VERSION "HIPBNNNYNNNNNNNNNNNNNNNNNNNNNNNNNNNNNNNNNN/4/%%/4/'%**4NNN///"

NS_ :

BS_:

BU_: EXXOTEST__XXX

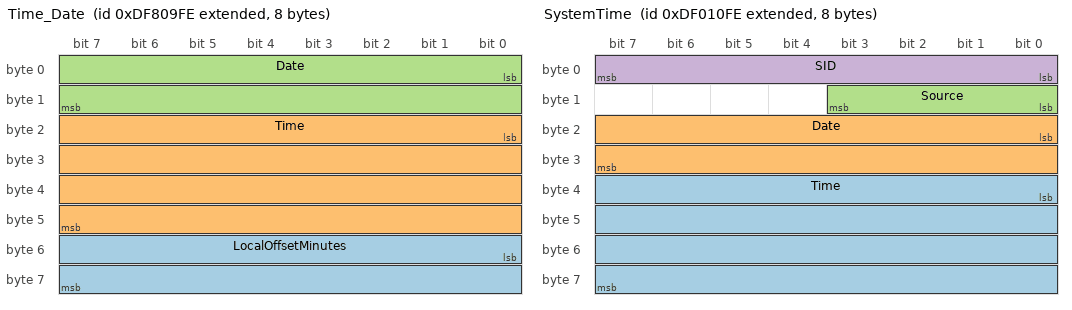
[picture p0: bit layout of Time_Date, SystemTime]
BO_ 2381842942 Time_Date: 8 EXXOTEST__XXX
 SG_ LocalOffsetMinutes : 48|16@1- (1,0) [-32764|32764] "mins"  EXXOTEST__XXX
 SG_ Time : 16|32@1+ (0.0001,0) [0|86401] "sec"  EXXOTEST__XXX
 SG_ Date : 0|16@1+ (1,0) [0|65532] "day"  EXXOTEST__XXX

BO_ 2381911550 TimeTo_FromMark: 10 EXXOTEST__XXX
 SG_ MarkID : 48|32@1+ (1,0) [0|4294967292] ""  EXXOTEST__XXX
 SG_ MarkType : 40|4@1+ (1,0) [0|15] ""  EXXOTEST__XXX
 SG_ TimeElapsedTogoToMark : 8|32@1- (0.001,0) [-2148000|2148000] "sec"  EXXOTEST__XXX
 SG_ SID : 0|8@1+ (1,0) [0|252] ""  EXXOTEST__XXX

BO_ 2583499006 TideStationData: 23 EXXOTEST__XXX
 SG_ StationNameString : 168|16@1+ (1,0) [0|255] "ASCII"  EXXOTEST__XXX
 SG_ StationIDString : 152|16@1+ (1,0) [0|255] "ASCII"  EXXOTEST__XXX
 SG_ TideLevelStandardDeviation : 136|16@1+ (0.01,0) [0|655.32] "m"  EXXOTEST__XXX
 SG_ TideLevel : 120|16@1- (0.001,0) [-32.764|32.764] "m"  EXXOTEST__XXX
 SG_ StationLocationLongitude : 88|32@1- (1,0) [-180|180] "deg"  EXXOTEST__XXX
 SG_ StationLocationLatitude : 56|32@1- (1,0) [-90|90] "deg"  EXXOTEST__XXX
 SG_ MeasurementTime : 24|32@1+ (0.0001,0) [0|86401] "sec"  EXXOTEST__XXX
 SG_ MeasurementDate : 8|16@1+ (1,0) [0|65532] "day"  EXXOTEST__XXX
 SG_ TideTendency : 4|2@1+ (1,0) [0|3] ""  EXXOTEST__XXX
 SG_ Mode : 0|4@1+ (1,0) [0|15] ""  EXXOTEST__XXX

BO_ 2381320446 SystemTime: 8 EXXOTEST__XXX
 SG_ Time : 32|32@1+ (0.0001,0) [0|86401] "sec"  EXXOTEST__XXX
 SG_ Date : 16|16@1+ (1,0) [0|65532] "day"  EXXOTEST__XXX
 SG_ Source : 8|4@1+ (1,0) [0|15] ""  EXXOTEST__XXX
 SG_ SID : 0|8@1+ (1,0) [0|252] ""  EXXOTEST__XXX

BO_ 2381451006 SwitchBankCtrl: 8 EXXOTEST__XXX
 SG_ Switch28 : 62|2@1+ (1,0) [0|3] ""  EXXOTEST__XXX
 SG_ Switch27 : 60|2@1+ (1,0) [0|3] ""  EXXOTEST__XXX
 SG_ Switch26 : 58|2@1+ (1,0) [0|3] ""  EXXOTEST__XXX
 SG_ Switch25 : 56|2@1+ (1,0) [0|3] ""  EXXOTEST__XXX
 SG_ Switch24 : 54|2@1+ (1,0) [0|3] ""  EXXOTEST__XXX
 SG_ Switch23 : 52|2@1+ (1,0) [0|3] ""  EXXOTEST__XXX
 SG_ Switch22 : 50|2@1+ (1,0) [0|3] ""  EXXOTEST__XXX
 SG_ Switch21 : 48|2@1+ (1,0) [0|3] ""  EXXOTEST__XXX
 SG_ Switch20 : 46|2@1+ (1,0) [0|3] ""  EXXOTEST__XXX
 SG_ Switch19 : 44|2@1+ (1,0) [0|3] ""  EXXOTEST__XXX
 SG_ Switch18 : 42|2@1+ (1,0) [0|3] ""  EXXOTEST__XXX
 SG_ Switch17 : 40|2@1+ (1,0) [0|3] ""  EXXOTEST__XXX
 SG_ Switch16 : 38|2@1+ (1,0) [0|3] ""  EXXOTEST__XXX
 SG_ Switch15 : 36|2@1+ (1,0) [0|3] ""  EXXOTEST__XXX
 SG_ Switch14 : 34|2@1+ (1,0) [0|3] ""  EXXOTEST__XXX
 SG_ Switch13 : 32|2@1+ (1,0) [0|3] ""  EXXOTEST__XXX
 SG_ Switch12 : 30|2@1+ (1,0) [0|3] ""  EXXOTEST__XXX
 SG_ Switch11 : 28|2@1+ (1,0) [0|3] ""  EXXOTEST__XXX
 SG_ Switch10 : 26|2@1+ (1,0) [0|3] ""  EXXOTEST__XXX
 SG_ Switch9 : 24|2@1+ (1,0) [0|3] ""  EXXOTEST__XXX
 SG_ Switch8 : 22|2@1+ (1,0) [0|3] ""  EXXOTEST__XXX
 SG_ Switch7 : 20|2@1+ (1,0) [0|3] ""  EXXOTEST__XXX
 SG_ Switch6 : 18|2@1+ (1,0) [0|3] ""  EXXOTEST__XXX
 SG_ Switch5 : 16|2@1+ (1,0) [0|3] ""  EXXOTEST__XXX
 SG_ Switch4 : 14|2@1+ (1,0) [0|3] ""  EXXOTEST__XXX
 SG_ Switch3 : 12|2@1+ (1,0) [0|3] ""  EXXOTEST__XXX
 SG_ Switch2 : 10|2@1+ (1,0) [0|3] ""  EXXOTEST__XXX
 SG_ Switch1 : 8|2@1+ (1,0) [0|3] ""  EXXOTEST__XXX
 SG_ SwitchBankInstance : 0|8@1+ (1,0) [0|252] ""  EXXOTEST__XXX

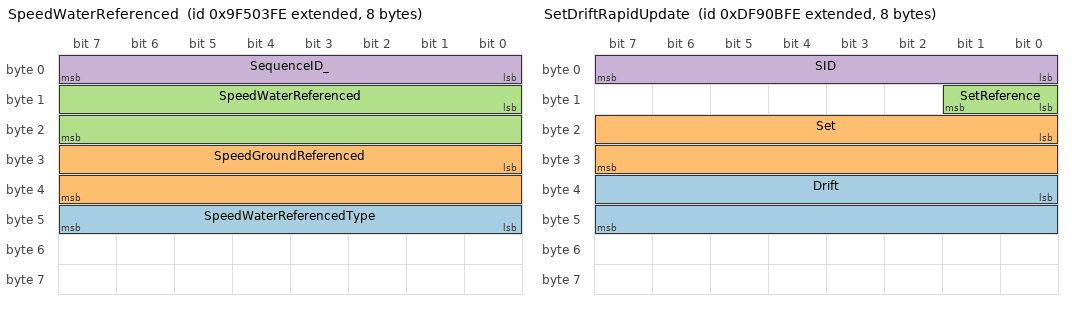
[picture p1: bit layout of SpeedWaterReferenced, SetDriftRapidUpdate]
BO_ 2314535934 SpeedWaterReferenced: 8 EXXOTEST__XXX
 SG_ SpeedWaterReferencedType : 40|8@1+ (1,0) [0|0] ""  EXXOTEST__XXX
 SG_ SpeedGroundReferenced : 24|16@1+ (0.01,0) [0|655.32] "m/s"  EXXOTEST__XXX
 SG_ SpeedWaterReferenced : 8|16@1+ (0.01,0) [0|655.32] "m/s"  EXXOTEST__XXX
 SG_ SequenceID_ : 0|8@1+ (1,0) [0|252] ""  EXXOTEST__XXX

BO_ 2315129086 SmallCraftStatus: 8 EXXOTEST__XXX
 SG_ StarboardTrimTab : 8|8@1- (1,0) [-124|124] ""  EXXOTEST__XXX
 SG_ PortTrimTab : 0|8@1- (1,0) [-124|124] ""  EXXOTEST__XXX

BO_ 2381908990 SetDriftRapidUpdate: 8 EXXOTEST__XXX
 SG_ Drift : 32|16@1+ (0.01,0) [0|655.32] "m/s"  EXXOTEST__XXX
 SG_ Set : 16|16@1+ (0.0001,0) [0|6.28318] "rad"  EXXOTEST__XXX
 SG_ SetReference : 8|2@1+ (1,0) [0|3] ""  EXXOTEST__XXX
 SG_ SID : 0|8@1+ (1,0) [0|252] ""  EXXOTEST__XXX

BO_ 2583499262 SalinityStationData: 25 EXXOTEST__XXX

BO_ 2650543102 RouteAndWPServiceRouteWPNamePos: 14 EXXOTEST__XXX
 SG_ WPName : 96|16@1+ (1,0) [0|255] "ASCII"  EXXOTEST__XXX
 SG_ WPID : 80|16@1+ (1,0) [0|65532] ""  EXXOTEST__XXX
 SG_ RouteID : 64|16@1+ (1,0) [0|65532] ""  EXXOTEST__XXX
 SG_ DatabaseID : 48|16@1+ (1,0) [0|65532] ""  EXXOTEST__XXX
 SG_ NumberOfWPsInRoute : 32|16@1+ (1,0) [0|65532] ""  EXXOTEST__XXX
 SG_ nItems : 16|16@1+ (1,0) [0|65532] ""  EXXOTEST__XXX
 SG_ StartRPS : 0|16@1+ (1,0) [0|65532] ""  EXXOTEST__XXX

BO_ 2650543358 RouteAndWPServiceRouteWPName: 14 EXXOTEST__XXX
 SG_ WPName : 96|16@1+ (1,0) [0|255] "ASCII"  EXXOTEST__XXX
 SG_ WPID : 80|16@1+ (1,0) [0|65532] ""  EXXOTEST__XXX
 SG_ RouteID : 64|16@1+ (1,0) [0|65532] ""  EXXOTEST__XXX
 SG_ DatabaseID : 48|16@1+ (1,0) [0|65532] ""  EXXOTEST__XXX
 SG_ NumberOfWPsInRoute : 32|16@1+ (1,0) [0|65532] ""  EXXOTEST__XXX
 SG_ nItems : 16|16@1+ (1,0) [0|65532] ""  EXXOTEST__XXX
 SG_ StartRPS : 0|16@1+ (1,0) [0|65532] ""  EXXOTEST__XXX

BO_ 2650542590 RouteAndWPServiceRouteList: 12 EXXOTEST__XXX
 SG_ RouteName : 80|16@1+ (1,0) [0|255] "ASCII"  EXXOTEST__XXX
 SG_ RouteID : 64|16@1+ (1,0) [0|65532] ""  EXXOTEST__XXX
 SG_ DatabaseID : 48|16@1+ (1,0) [0|65532] ""  EXXOTEST__XXX
 SG_ NmbrOfRoutesAvailableInDatabase : 32|16@1+ (1,0) [0|65532] ""  EXXOTEST__XXX
 SG_ nItems : 16|16@1+ (1,0) [0|65532] ""  EXXOTEST__XXX
 SG_ StartRouteID : 0|16@1+ (1,0) [0|65532] ""  EXXOTEST__XXX

BO_ 2650544126 RouteAndWPServiceRouteComment: 13 EXXOTEST__XXX
 SG_ Comment : 80|24@1+ (1,0) [0|255] ""  EXXOTEST__XXX
 SG_ RouteID : 64|16@1+ (1,0) [0|65532] ""  EXXOTEST__XXX
 SG_ DatabaseID : 48|16@1+ (1,0) [0|65532] ""  EXXOTEST__XXX
 SG_ NumberOfRoutesWithComments : 32|16@1+ (1,0) [0|65532] ""  EXXOTEST__XXX
 SG_ nItems : 16|16@1+ (1,0) [0|65532] ""  EXXOTEST__XXX
 SG_ StartRouteID : 0|16@1+ (1,0) [0|65532] ""  EXXOTEST__XXX

BO_ 2650544638 RouteAndWPServiceRadiusOfTurn: 14 EXXOTEST__XXX
 SG_ RadiusOfTurn : 96|16@1- (1,0) [-32764|32764] "m"  EXXOTEST__XXX
 SG_ RPS : 80|16@1+ (1,0) [0|65532] ""  EXXOTEST__XXX
 SG_ RouteID : 64|16@1+ (1,0) [0|65532] ""  EXXOTEST__XXX
 SG_ DatabaseID : 48|16@1+ (1,0) [0|65532] ""  EXXOTEST__XXX
 SG_ NmbrOfWypntsWthASpcfcRdusOfTurn : 32|16@1+ (1,0) [0|65532] ""  EXXOTEST__XXX
 SG_ nItems : 16|16@1+ (1,0) [0|65532] ""  EXXOTEST__XXX
 SG_ StartRPS : 0|16@1+ (1,0) [0|65532] ""  EXXOTEST__XXX

BO_ 2650542334 RouteAndWPServiceDatabaseList: 10 EXXOTEST__XXX
 SG_ DatabaseName : 64|16@1+ (1,0) [0|255] "ASCII"  EXXOTEST__XXX
 SG_ DatabaseID : 48|16@1+ (1,0) [0|65532] ""  EXXOTEST__XXX
 SG_ NumberOfDatabasesAvailable : 32|16@1+ (1,0) [0|65532] ""  EXXOTEST__XXX
 SG_ nItems : 16|16@1+ (1,0) [0|65532] ""  EXXOTEST__XXX
 SG_ StartDatabaseID : 0|16@1+ (1,0) [0|65532] ""  EXXOTEST__XXX

BO_ 2314277886 RateOfTurn: 8 EXXOTEST__XXX
 SG_ RateOfTurn : 8|16@1- (1,0) [-32768|32767] "rad/s"  EXXOTEST__XXX
 SG_ SequenceID_ : 0|8@1+ (1,0) [0|252] ""  EXXOTEST__XXX

BO_ 2382039038 RadioFrequency_Mode_Power: 14 EXXOTEST__XXX
 SG_ RadioChannel : 64|48@1+ (1,0) [0|255] "ASCII"  EXXOTEST__XXX
 SG_ TxFrequency : 32|32@1+ (10,0) [0|327040] "Hz"  EXXOTEST__XXX
 SG_ RxFrequency : 0|32@1+ (10,0) [0|327040] "Hz"  EXXOTEST__XXX

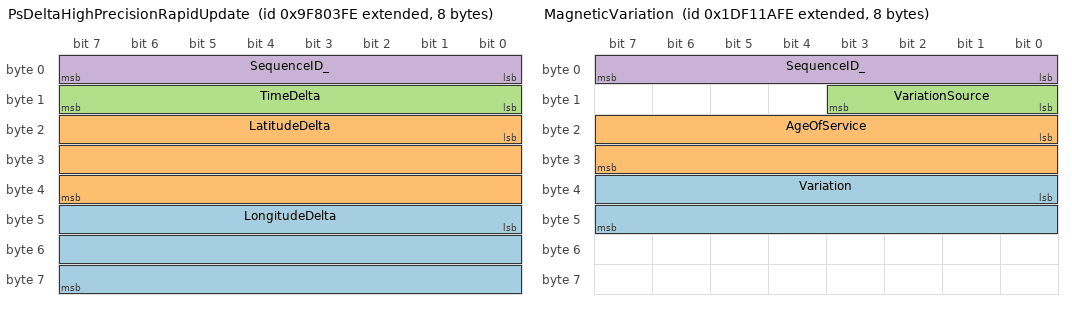
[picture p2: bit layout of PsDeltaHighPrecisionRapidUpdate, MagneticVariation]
BO_ 2314732542 PsDeltaHighPrecisionRapidUpdate: 8 EXXOTEST__XXX
 SG_ LongitudeDelta : 40|24@1- (1E-05,0) [-83|83] "s"  EXXOTEST__XXX
 SG_ LatitudeDelta : 16|24@1- (1E-05,0) [-83|83] "s"  EXXOTEST__XXX
 SG_ TimeDelta : 8|8@1+ (0.005,0) [0|1.26] "sec"  EXXOTEST__XXX
 SG_ SequenceID_ : 0|8@1+ (1,0) [0|252] ""  EXXOTEST__XXX

BO_ 2314732030 PosRapidUpdate: 8 EXXOTEST__XXX
 SG_ Longitude_ : 32|32@1- (1,0) [-180|180] "deg"  EXXOTEST__XXX
 SG_ Latitude_ : 0|32@1- (1,0) [-90|90] "deg"  EXXOTEST__XXX

BO_ 2583234046 NavigationRoute_WPInformation: 16 EXXOTEST__XXX
 SG_ WPName : 112|16@1+ (1,0) [0|255] "ASCII"  EXXOTEST__XXX
 SG_ RouteName : 72|16@1+ (1,0) [0|255] "ASCII"  EXXOTEST__XXX
 SG_ SpplmntaryRoute_WPDataAvailable : 68|2@1+ (1,0) [0|3] ""  EXXOTEST__XXX
 SG_ NavigationDirectionInRoute : 64|4@1+ (1,0) [0|15] ""  EXXOTEST__XXX
 SG_ RouteID : 48|16@1+ (1,0) [0|65532] ""  EXXOTEST__XXX
 SG_ DatabaseID : 32|16@1+ (1,0) [0|65532] ""  EXXOTEST__XXX
 SG_ nItems : 16|16@1+ (1,0) [0|65532] ""  EXXOTEST__XXX
 SG_ StartRPS : 0|16@1+ (1,0) [0|65532] ""  EXXOTEST__XXX

BO_ 2381907198 NavigationData: 34 EXXOTEST__XXX
 SG_ WaypointClosingVelocity : 256|16@1- (0.01,0) [-327.66|327.66] "m/s"  EXXOTEST__XXX
 SG_ DestinationWptLongitude : 224|32@1- (1,0) [-180|180] "deg"  EXXOTEST__XXX
 SG_ DestinationWptLatitude : 192|32@1- (1,0) [-90|90] "deg"  EXXOTEST__XXX
 SG_ DestinationWaypointNumber : 160|32@1+ (1,0) [0|4294967292] ""  EXXOTEST__XXX
 SG_ OriginWaypointNumber : 128|32@1+ (1,0) [0|4294967292] ""  EXXOTEST__XXX
 SG_ BearingPosToDestinationWaypoint : 112|16@1+ (0.0001,0) [0|6.28318] "rad"  EXXOTEST__XXX
 SG_ BaringiginToDestinationWaypoint : 96|16@1+ (0.0001,0) [0|6.28318] "rad"  EXXOTEST__XXX
 SG_ ETADate : 80|16@1+ (1,0) [0|65532] "day"  EXXOTEST__XXX
 SG_ ETATime : 48|32@1+ (0.0001,0) [0|86401] "sec"  EXXOTEST__XXX
 SG_ CalculationType : 46|2@1+ (1,0) [0|3] ""  EXXOTEST__XXX
 SG_ ArrivalCircleEntered : 44|2@1+ (1,0) [0|3] ""  EXXOTEST__XXX
 SG_ PerpendicularCrossed : 42|2@1+ (1,0) [0|3] ""  EXXOTEST__XXX
 SG_ Course_BearingRef : 40|2@1+ (1,0) [0|3] ""  EXXOTEST__XXX
 SG_ DistanceToDestinationWaypoint : 8|32@1+ (0.01,0) [0|42950000] "m"  EXXOTEST__XXX
 SG_ SID : 0|8@1+ (1,0) [0|252] ""  EXXOTEST__XXX

BO_ 2381184766 NMEARqGroupFunction: 15 EXXOTEST__XXX
 SG_ NumberOfRqedCmdedParameters m2 : 48|8@1+ (1,0) [0|252] ""  EXXOTEST__XXX
 SG_ VrblNmbrOfFldsFldNmber6Repeated3 m2 : 44|4@1+ (1,0) [0|15] ""  EXXOTEST__XXX
 SG_ FirstParameterErrorCode m2 : 40|4@1+ (1,0) [0|15] ""  EXXOTEST__XXX
 SG_ TransInterval_PriorityErrorCode m2 : 36|4@1+ (1,0) [0|15] ""  EXXOTEST__XXX
 SG_ RqedCmdedPGNBeingAcknowledged m2 : 12|24@1+ (1,0) [0|16777215] ""  EXXOTEST__XXX
 SG_ PGNErrorCode m2 : 8|4@1+ (1,0) [0|15] ""  EXXOTEST__XXX
 SG_ VrblNmbrOfFldsFldNmber6Repeated2 m1 : 56|8@1+ (1,0) [0|252] ""  EXXOTEST__XXX
 SG_ FeldNumberOfFirstCmdedParameter m1 : 48|8@1+ (1,0) [0|252] ""  EXXOTEST__XXX
 SG_ NmbrOfPrsOfCmddPrmetersToFollow m1 : 40|8@1+ (1,0) [0|252] ""  EXXOTEST__XXX
 SG_ PrioritySetting m1 : 32|4@1+ (1,0) [0|15] ""  EXXOTEST__XXX
 SG_ CmdedPGN m1 : 8|24@1+ (1,0) [0|16777215] ""  EXXOTEST__XXX
 SG_ VrblNmbrOfFldsFldNmber6Repeated m0 : 96|8@1+ (1,0) [0|252] ""  EXXOTEST__XXX
 SG_ FieldNumberOfFirstRqedParameter m0 : 88|8@1+ (1,0) [0|252] ""  EXXOTEST__XXX
 SG_ NmbrOfPrsOfRqParametersToFollow m0 : 80|8@1+ (1,0) [0|252] ""  EXXOTEST__XXX
 SG_ TransIntervalOffset m0 : 64|16@1+ (0.01,0) [0|655.32] "sec"  EXXOTEST__XXX
 SG_ TransInterval m0 : 32|32@1+ (0.001,0) [0|4295000] "sec"  EXXOTEST__XXX
 SG_ RqedPGN m0 : 8|24@1+ (1,0) [0|16777215] ""  EXXOTEST__XXX
 SG_ GroupFunctionRq_Cmd_Acknowledge M : 0|8@1+ (1,0) [0|252] ""  EXXOTEST__XXX

BO_ 2583500030 MooredBuoyStationData: 36 EXXOTEST__XXX
 SG_ StationIDString : 272|16@1+ (1,0) [0|255] "ASCII"  EXXOTEST__XXX
 SG_ WaterTemp : 256|16@1+ (0.01,0) [0|655.32] "°K"  EXXOTEST__XXX
 SG_ AirTemp : 240|16@1+ (0.01,0) [0|655.32] "°K"  EXXOTEST__XXX
 SG_ PressTendencyRate : 224|16@1- (10,0) [-327640|327640] "Pa/hr"  EXXOTEST__XXX
 SG_ AtmosphericPress : 208|16@1+ (100,0) [0|6553200] "Pa"  EXXOTEST__XXX
 SG_ DominateWavePeriod : 192|16@1+ (0.01,0) [0|655.32] "sec"  EXXOTEST__XXX
 SG_ WaveHeight : 176|16@1+ (0.01,0) [0|655.32] "m"  EXXOTEST__XXX
 SG_ WindGusts : 160|16@1+ (0.01,0) [0|655.32] "m/s"  EXXOTEST__XXX
 SG_ WindReference : 152|3@1+ (1,0) [0|7] ""  EXXOTEST__XXX
 SG_ WindDirection : 136|16@1+ (0.0001,0) [0|6.28318] "rad"  EXXOTEST__XXX
 SG_ WindSpeed : 120|16@1+ (0.01,0) [0|655.32] "m/s"  EXXOTEST__XXX
 SG_ StationLocationLongitude : 88|32@1- (1,0) [-180|180] "deg"  EXXOTEST__XXX
 SG_ StationLocationLatitude : 56|32@1- (1,0) [-90|90] "deg"  EXXOTEST__XXX
 SG_ MeasurementTime : 24|32@1+ (0.0001,0) [0|86401] "sec"  EXXOTEST__XXX
 SG_ MeasurementDate : 8|16@1+ (1,0) [0|65532] "day"  EXXOTEST__XXX
 SG_ Mode : 0|4@1+ (1,0) [0|15] ""  EXXOTEST__XXX

BO_ 2583499774 MeteorologicalStationData: 30 EXXOTEST__XXX
 SG_ StationNameString : 224|16@1+ (1,0) [0|255] "ASCII"  EXXOTEST__XXX
 SG_ StationIDString : 208|16@1+ (1,0) [0|255] "ASCII"  EXXOTEST__XXX
 SG_ AirTemp : 192|16@1+ (0.01,0) [0|655.32] "°K"  EXXOTEST__XXX
 SG_ AtmosphericPress : 176|16@1+ (100,0) [0|6553200] "Pa"  EXXOTEST__XXX
 SG_ WindGusts : 160|16@1+ (0.01,0) [0|655.32] "m/s"  EXXOTEST__XXX
 SG_ WindReference : 152|3@1+ (1,0) [0|7] ""  EXXOTEST__XXX
 SG_ WindDirection : 136|16@1+ (0.0001,0) [0|6.28318] "rad"  EXXOTEST__XXX
 SG_ WindSpeed : 120|16@1+ (0.01,0) [0|655.32] "m/s"  EXXOTEST__XXX
 SG_ StationLocationLongitude : 88|32@1- (1,0) [-180|180] "deg"  EXXOTEST__XXX
 SG_ StationLocationLatitude : 56|32@1- (1,0) [-90|90] "deg"  EXXOTEST__XXX
 SG_ MeasurementTime : 24|32@1+ (0.0001,0) [0|86401] "sec"  EXXOTEST__XXX
 SG_ MeasurementDate : 8|16@1+ (1,0) [0|65532] "day"  EXXOTEST__XXX
 SG_ Mode : 0|4@1+ (1,0) [0|15] ""  EXXOTEST__XXX

BO_ 2649823998 MagneticVariation: 8 EXXOTEST__XXX
 SG_ Variation : 32|16@1- (0.0001,0) [-3.14159|3.14159] "rad"  EXXOTEST__XXX
 SG_ AgeOfService : 16|16@1+ (1,0) [0|65532] "day"  EXXOTEST__XXX
 SG_ VariationSource : 8|4@1+ (1,0) [0|15] ""  EXXOTEST__XXX
 SG_ SequenceID_ : 0|8@1+ (1,0) [0|252] ""  EXXOTEST__XXX

BO_ 2382103806 LoranCTDData: 32 EXXOTEST__XXX
 SG_ Mode : 248|4@1+ (1,0) [0|15] ""  EXXOTEST__XXX
 SG_ StationStatusZ : 244|4@1+ (1,0) [0|15] ""  EXXOTEST__XXX
 SG_ StationStatusY : 240|4@1+ (1,0) [0|15] ""  EXXOTEST__XXX
 SG_ StationStatusX : 236|4@1+ (1,0) [0|15] ""  EXXOTEST__XXX
 SG_ StationStatusW : 232|4@1+ (1,0) [0|15] ""  EXXOTEST__XXX
 SG_ StationStatusV : 228|4@1+ (1,0) [0|15] ""  EXXOTEST__XXX
 SG_ StationStatusMaster : 224|4@1+ (1,0) [0|15] ""  EXXOTEST__XXX
 SG_ ZSecondTD : 192|32@1- (1,0) [-2.14|2.14] "sec"  EXXOTEST__XXX
 SG_ YSecondTD : 160|32@1- (1,0) [-2.14|2.14] "sec"  EXXOTEST__XXX
 SG_ XSecondTD : 128|32@1- (1,0) [-2.14|2.14] "sec"  EXXOTEST__XXX
 SG_ WSecondTD : 96|32@1- (1,0) [-2.14|2.14] "sec"  EXXOTEST__XXX
 SG_ VSecondTD : 64|32@1- (1,0) [-2.14|2.14] "sec"  EXXOTEST__XXX
 SG_ MasterRange : 32|32@1- (1,0) [-2.14|2.14] "sec"  EXXOTEST__XXX
 SG_ GroupRepetitionInterval : 0|32@1- (1,0) [-2.14|2.14] "sec"  EXXOTEST__XXX

BO_ 2382104318 LoranCSignalData: 8 EXXOTEST__XXX
 SG_ StationIdentifier : 32|8@1+ (1,0) [0|255] "ASCII"  EXXOTEST__XXX
 SG_ GroupRepetitionInterval : 0|32@1- (1,0) [-2.14|2.14] "sec"  EXXOTEST__XXX

BO_ 2382104062 LoranCRangeData: 32 EXXOTEST__XXX
 SG_ Mode : 248|4@1+ (1,0) [0|15] ""  EXXOTEST__XXX
 SG_ StationStatusZ : 244|4@1+ (1,0) [0|15] ""  EXXOTEST__XXX
 SG_ StationStatusY : 240|4@1+ (1,0) [0|15] ""  EXXOTEST__XXX
 SG_ StationStatusX : 236|4@1+ (1,0) [0|15] ""  EXXOTEST__XXX
 SG_ StationStatusW : 232|4@1+ (1,0) [0|15] ""  EXXOTEST__XXX
 SG_ StationStatusV : 228|4@1+ (1,0) [0|15] ""  EXXOTEST__XXX
 SG_ StationStatusMaster : 224|4@1+ (1,0) [0|15] ""  EXXOTEST__XXX
 SG_ ZSecondRange : 192|32@1- (1,0) [-2.14|2.14] "sec"  EXXOTEST__XXX
 SG_ YSecondRange : 160|32@1- (1,0) [-2.14|2.14] "sec"  EXXOTEST__XXX
 SG_ XSecondRange : 128|32@1- (1,0) [-2.14|2.14] "sec"  EXXOTEST__XXX
 SG_ WSecondRange : 96|32@1- (1,0) [-2.14|2.14] "sec"  EXXOTEST__XXX
 SG_ VSecondRange : 64|32@1- (1,0) [-2.14|2.14] "sec"  EXXOTEST__XXX
 SG_ MasterRange : 32|32@1- (1,0) [-2.14|2.14] "sec"  EXXOTEST__XXX
 SG_ GroupRepetitionInterval : 0|32@1- (1,0) [-2.14|2.14] "sec"  EXXOTEST__XXX

BO_ 2314274302 Heading_TrackCtrl: 21 EXXOTEST__XXX
 SG_ VesselHeading : 152|16@1+ (0.0001,0) [0|6.28318] "rad"  EXXOTEST__XXX
 SG_ OffTrackLimit : 136|16@1- (1,0) [-32764|32764] "m"  EXXOTEST__XXX
 SG_ RateOfTurnder : 120|16@1- (1,0) [-1|1] "rad/s"  EXXOTEST__XXX
 SG_ RadiusOfTurnder : 104|16@1- (1,0) [-32764|32764] "m"  EXXOTEST__XXX
 SG_ OffHeadingLimit : 88|16@1+ (0.0001,0) [0|6.28318] "rad"  EXXOTEST__XXX
 SG_ RudderLimit : 72|16@1+ (0.0001,0) [0|6.28318] "rad"  EXXOTEST__XXX
 SG_ Track : 56|16@1+ (0.0001,0) [0|6.28318] "rad"  EXXOTEST__XXX
 SG_ HeadingToSteer : 40|16@1+ (0.0001,0) [0|6.28318] "rad"  EXXOTEST__XXX
 SG_ CmdedRudderAngle : 24|16@1- (0.0001,0) [-3.14159|3.14159] "rad"  EXXOTEST__XXX
 SG_ CmdedRudderDirection : 21|3@1+ (1,0) [0|7] ""  EXXOTEST__XXX
 SG_ HeadingReference : 14|2@1+ (1,0) [0|3] ""  EXXOTEST__XXX
 SG_ TurnMode : 11|3@1+ (1,0) [0|7] ""  EXXOTEST__XXX
 SG_ SteerMode : 8|3@1+ (1,0) [0|7] ""  EXXOTEST__XXX
 SG_ Override : 6|2@1+ (1,0) [0|3] ""  EXXOTEST__XXX
 SG_ OffTrackLimitExceeded : 4|2@1+ (1,0) [0|3] ""  EXXOTEST__XXX
 SG_ OffHeadingLimitExceeded : 2|2@1+ (1,0) [0|3] ""  EXXOTEST__XXX
 SG_ RudderLimitExceeded : 0|2@1+ (1,0) [0|3] ""  EXXOTEST__XXX

BO_ 2583299582 GPSAlmanacData: 26 EXXOTEST__XXX
 SG_ ClockParameter2 : 195|11@1+ (1,0) [0|2047] ""  EXXOTEST__XXX
 SG_ ClockParameter1 : 184|11@1+ (1,0) [0|2047] ""  EXXOTEST__XXX
 SG_ MeanAnomaly : 160|24@1+ (1,0) [0|16777215] ""  EXXOTEST__XXX
 SG_ LongitudeOfAscensionNode : 136|24@1+ (1,0) [0|16777215] ""  EXXOTEST__XXX
 SG_ ArgumentOfPerigee : 112|24@1+ (1,0) [0|16777215] ""  EXXOTEST__XXX
 SG_ RootOfSemimajorAxis : 88|24@1+ (1,0) [0|16777215] ""  EXXOTEST__XXX
 SG_ RateOfRightAscension : 72|16@1+ (1,0) [0|65535] ""  EXXOTEST__XXX
 SG_ InclinationAngle : 56|16@1+ (1,0) [0|65535] ""  EXXOTEST__XXX
 SG_ AlmanacReferenceTime : 48|8@1+ (1,0) [0|255] ""  EXXOTEST__XXX
 SG_ Eccentricity : 32|16@1+ (1,0) [0|65535] ""  EXXOTEST__XXX
 SG_ SVHealthBits : 24|8@1+ (1,0) [0|255] ""  EXXOTEST__XXX
 SG_ GPSWeekNumber : 8|16@1+ (1,0) [0|65532] ""  EXXOTEST__XXX
 SG_ PRN : 0|8@1+ (1,0) [0|252] ""  EXXOTEST__XXX

BO_ 2583299326 GNSSSatsInView: 27 EXXOTEST__XXX
 SG_ PRNStatusN : 208|4@1+ (1,0) [0|15] ""  EXXOTEST__XXX
 SG_ RangeResidualsN : 176|32@1- (1E-05,0) [-21470|21470] "m"  EXXOTEST__XXX
 SG_ SNRN : 160|16@1- (0.01,0) [-327.64|327.64] "dB"  EXXOTEST__XXX
 SG_ AzimuthN : 144|16@1+ (0.0001,0) [0|6.28318] "rad"  EXXOTEST__XXX
 SG_ ElevationN : 128|16@1- (0.0001,0) [-3.14159|3.14159] "rad"  EXXOTEST__XXX
 SG_ PRNN : 120|8@1+ (1,0) [0|252] ""  EXXOTEST__XXX
 SG_ PRNStatus1 : 112|4@1+ (1,0) [0|15] ""  EXXOTEST__XXX
 SG_ RangeResiduals1 : 80|32@1- (1E-05,0) [-21470|21470] "m"  EXXOTEST__XXX
 SG_ SNR1 : 64|16@1- (0.01,0) [-327.64|327.64] "dB"  EXXOTEST__XXX
 SG_ Azimuth1 : 48|16@1+ (0.0001,0) [0|6.28318] "rad"  EXXOTEST__XXX
 SG_ Elevation1 : 32|16@1- (0.0001,0) [-3.14159|3.14159] "rad"  EXXOTEST__XXX
 SG_ PRN1 : 24|8@1+ (1,0) [0|252] ""  EXXOTEST__XXX
 SG_ NumberOfSVs_ : 16|8@1+ (1,0) [0|252] ""  EXXOTEST__XXX
 SG_ SID : 0|8@1+ (1,0) [0|252] ""  EXXOTEST__XXX
 SG_ RangeResidualMode : 8|2@1- (1,0) [0|3] ""  EXXOTEST__XXX

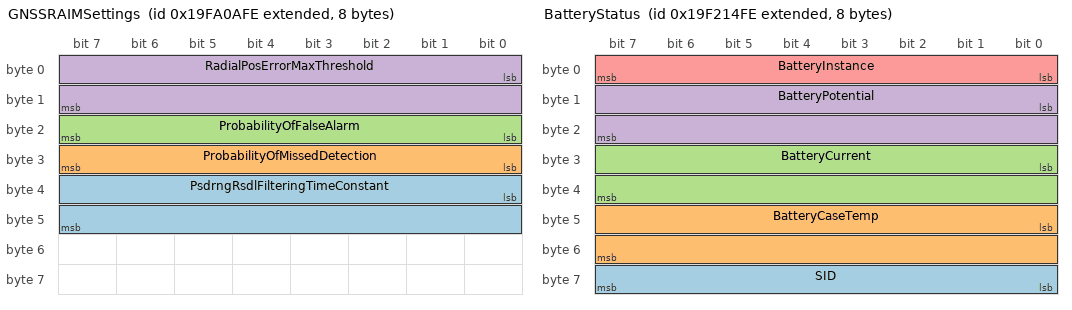
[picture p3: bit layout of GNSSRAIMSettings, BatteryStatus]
BO_ 2583300862 GNSSRAIMSettings: 8 EXXOTEST__XXX
 SG_ PsdrngRsdlFilteringTimeConstant : 32|16@1+ (1,0) [0|65532] "sec"  EXXOTEST__XXX
 SG_ ProbabilityOfMissedDetection : 24|8@1- (1,0) [-124|124] "%"  EXXOTEST__XXX
 SG_ ProbabilityOfFalseAlarm : 16|8@1- (1,0) [-124|124] ""  EXXOTEST__XXX
 SG_ RadialPosErrorMaxThreshold : 0|16@1+ (0.01,0) [0|655.32] "m"  EXXOTEST__XXX

BO_ 2583238398 BringAndDistanceBetweenTwoMarks: 17 EXXOTEST__XXX
 SG_ DestinationMarkID : 104|32@1+ (1,0) [0|4294967292] ""  EXXOTEST__XXX
 SG_ OriginMarkId : 72|32@1+ (1,0) [0|4294967292] ""  EXXOTEST__XXX
 SG_ DestinationMarkType : 68|4@1+ (1,0) [0|15] ""  EXXOTEST__XXX
 SG_ OriginMarkType : 64|4@1+ (1,0) [0|15] ""  EXXOTEST__XXX
 SG_ Distance : 32|32@1- (0.01,0) [-21470000|21470000] "m"  EXXOTEST__XXX
 SG_ BearingiginToDestination : 16|16@1+ (0.0001,0) [0|6.28318] "rad"  EXXOTEST__XXX
 SG_ CalculationType : 10|2@1+ (1,0) [0|3] ""  EXXOTEST__XXX
 SG_ BearingRef : 8|2@1+ (1,0) [0|3] ""  EXXOTEST__XXX
 SG_ SID : 0|8@1+ (1,0) [0|252] ""  EXXOTEST__XXX

BO_ 2381450750 BinarySwitchBankStatus: 8 EXXOTEST__XXX
 SG_ Indic28 : 62|2@1+ (1,0) [0|3] ""  EXXOTEST__XXX
 SG_ Indic27 : 60|2@1+ (1,0) [0|3] ""  EXXOTEST__XXX
 SG_ Indic26 : 58|2@1+ (1,0) [0|3] ""  EXXOTEST__XXX
 SG_ Indic25 : 56|2@1+ (1,0) [0|3] ""  EXXOTEST__XXX
 SG_ Indic24 : 54|2@1+ (1,0) [0|3] ""  EXXOTEST__XXX
 SG_ Indic23 : 52|2@1+ (1,0) [0|3] ""  EXXOTEST__XXX
 SG_ Indic22 : 50|2@1+ (1,0) [0|3] ""  EXXOTEST__XXX
 SG_ Indic21 : 48|2@1+ (1,0) [0|3] ""  EXXOTEST__XXX
 SG_ Indic20 : 46|2@1+ (1,0) [0|3] ""  EXXOTEST__XXX
 SG_ Indic19 : 44|2@1+ (1,0) [0|3] ""  EXXOTEST__XXX
 SG_ Indic18 : 42|2@1+ (1,0) [0|3] ""  EXXOTEST__XXX
 SG_ Indic17 : 40|2@1+ (1,0) [0|3] ""  EXXOTEST__XXX
 SG_ Indic16 : 38|2@1+ (1,0) [0|3] ""  EXXOTEST__XXX
 SG_ Indic15 : 36|2@1+ (1,0) [0|3] ""  EXXOTEST__XXX
 SG_ Indic14 : 34|2@1+ (1,0) [0|3] ""  EXXOTEST__XXX
 SG_ Indic13 : 32|2@1+ (1,0) [0|3] ""  EXXOTEST__XXX
 SG_ Indic12 : 30|2@1+ (1,0) [0|3] ""  EXXOTEST__XXX
 SG_ Indic11 : 28|2@1+ (1,0) [0|3] ""  EXXOTEST__XXX
 SG_ Indic10 : 26|2@1+ (1,0) [0|3] ""  EXXOTEST__XXX
 SG_ Indic9 : 24|2@1+ (1,0) [0|3] ""  EXXOTEST__XXX
 SG_ Indic8 : 22|2@1+ (1,0) [0|3] ""  EXXOTEST__XXX
 SG_ Indic7 : 20|2@1+ (1,0) [0|3] ""  EXXOTEST__XXX
 SG_ Indic6 : 18|2@1+ (1,0) [0|3] ""  EXXOTEST__XXX
 SG_ Indic5 : 16|2@1+ (1,0) [0|3] ""  EXXOTEST__XXX
 SG_ Indic4 : 14|2@1+ (1,0) [0|3] ""  EXXOTEST__XXX
 SG_ Indic3 : 12|2@1+ (1,0) [0|3] ""  EXXOTEST__XXX
 SG_ Indic2 : 10|2@1+ (1,0) [0|3] ""  EXXOTEST__XXX
 SG_ Indic1 : 8|2@1+ (1,0) [0|3] ""  EXXOTEST__XXX
 SG_ IndicatorBankInstance : 0|8@1+ (1,0) [0|252] ""  EXXOTEST__XXX

BO_ 2582779134 BatteryStatus: 8 EXXOTEST__XXX
 SG_ SID : 56|8@1+ (1,0) [0|252] ""  EXXOTEST__XXX
 SG_ BatteryCaseTemp : 40|16@1+ (0.01,0) [0|655.32] "°K"  EXXOTEST__XXX
 SG_ BatteryCurrent : 24|16@1- (0.1,0) [-3276.4|3276.4] "A"  EXXOTEST__XXX
 SG_ BatteryPotential : 8|16@1- (0.01,0) [-327.64|327.64] "V"  EXXOTEST__XXX
 SG_ BatteryInstance : 0|8@1+ (1,0) [0|252] ""  EXXOTEST__XXX

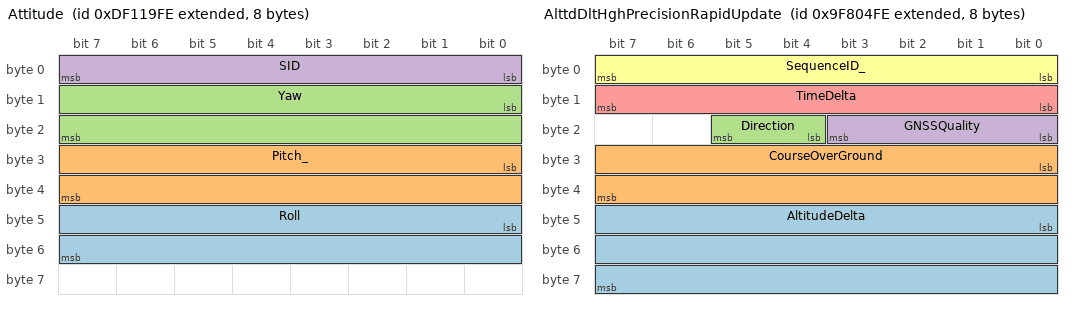
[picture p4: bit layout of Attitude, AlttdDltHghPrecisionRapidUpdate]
BO_ 2381388286 Attitude: 8 EXXOTEST__XXX
 SG_ Roll : 40|16@1- (0.0001,0) [-3.14159|3.14159] "rad"  EXXOTEST__XXX
 SG_ Pitch_ : 24|16@1+ (0.0001,0) [-3.14159|3.14159] "rad"  EXXOTEST__XXX
 SG_ Yaw : 8|16@1- (0.0001,0) [-3.14159|3.14159] "rad"  EXXOTEST__XXX
 SG_ SID : 0|8@1+ (1,0) [0|252] ""  EXXOTEST__XXX

BO_ 2314732798 AlttdDltHghPrecisionRapidUpdate: 8 EXXOTEST__XXX
 SG_ AltitudeDelta : 40|24@1- (0.001,0) [-8388|8388] "m"  EXXOTEST__XXX
 SG_ CourseOverGround : 24|16@1+ (0.0001,0) [0|6.28318] "rad"  EXXOTEST__XXX
 SG_ Direction : 20|2@1+ (1,0) [0|3] ""  EXXOTEST__XXX
 SG_ GNSSQuality : 16|4@1+ (1,0) [0|15] ""  EXXOTEST__XXX
 SG_ TimeDelta : 8|8@1+ (0.005,0) [0|1.26] "sec"  EXXOTEST__XXX
 SG_ SequenceID_ : 0|8@1+ (1,0) [0|252] ""  EXXOTEST__XXX

BO_ 2650474750 AISUTC_DateInquiry: 11 EXXOTEST__XXX
 SG_ DestinationID : 48|32@1+ (1,0) [0|4294967292] ""  EXXOTEST__XXX
 SG_ AISTransceiverInformation : 41|5@1+ (1,0) [0|31] ""  EXXOTEST__XXX
 SG_ SourceID : 8|32@1+ (1,0) [0|4294967292] ""  EXXOTEST__XXX
 SG_ RepeatIndicator : 6|2@1+ (1,0) [0|3] ""  EXXOTEST__XXX
 SG_ MsgID : 0|6@1+ (1,0) [0|63] ""  EXXOTEST__XXX

BO_ 2650472958 AISUTCAndDateReport: 26 EXXOTEST__XXX
 SG_ TypeOfElectronicPosingDevice : 188|4@1+ (1,0) [0|15] ""  EXXOTEST__XXX
 SG_ PosDate : 168|16@1+ (1,0) [0|65532] "day"  EXXOTEST__XXX
 SG_ AISTransceiverInformation : 163|5@1+ (1,0) [0|31] ""  EXXOTEST__XXX
 SG_ CommunicationState : 144|19@1+ (1,0) [0|524287] ""  EXXOTEST__XXX
 SG_ PosTime : 112|32@1+ (0.0001,0) [0|86401] "sec"  EXXOTEST__XXX
 SG_ RAIMflag : 105|1@1+ (1,0) [0|1] ""  EXXOTEST__XXX
 SG_ PosAccuracy : 104|1@1+ (1,0) [0|1] ""  EXXOTEST__XXX
 SG_ Latitude_ : 72|32@1- (1,0) [-90|90] "deg"  EXXOTEST__XXX
 SG_ Longitude_ : 40|32@1- (1,0) [-180|180] "deg"  EXXOTEST__XXX
 SG_ UserID : 8|32@1+ (1,0) [0|4294967292] ""  EXXOTEST__XXX
 SG_ RepeatIndicator : 6|2@1+ (1,0) [0|3] ""  EXXOTEST__XXX
 SG_ MsgID : 0|6@1+ (1,0) [0|63] ""  EXXOTEST__XXX

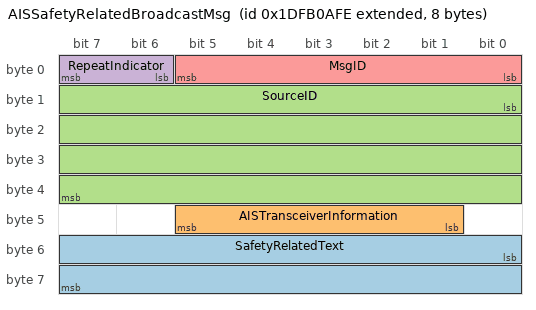
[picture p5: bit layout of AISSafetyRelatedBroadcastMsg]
BO_ 2650475262 AISSafetyRelatedBroadcastMsg: 8 EXXOTEST__XXX
 SG_ SafetyRelatedText : 48|16@1+ (1,0) [0|255] ""  EXXOTEST__XXX
 SG_ AISTransceiverInformation : 41|5@1+ (1,0) [0|31] ""  EXXOTEST__XXX
 SG_ SourceID : 8|32@1+ (1,0) [0|4294967292] ""  EXXOTEST__XXX
 SG_ RepeatIndicator : 6|2@1+ (1,0) [0|3] ""  EXXOTEST__XXX
 SG_ MsgID : 0|6@1+ (1,0) [0|63] ""  EXXOTEST__XXX

BO_ 2650474238 AISSARAircraftPosReport: 27 EXXOTEST__XXX
 SG_ DataTerminalEquipment : 208|1@1+ (1,0) [0|1] ""  EXXOTEST__XXX
 SG_ Altitude_ : 168|32@1- (0.01,0) [-21470000|21470000] "m"  EXXOTEST__XXX
 SG_ AISTransceiverInformation : 163|5@1+ (1,0) [0|31] ""  EXXOTEST__XXX
 SG_ CommunicationState : 144|19@1+ (1,0) [0|524287] ""  EXXOTEST__XXX
 SG_ SOG : 128|16@1+ (0.01,0) [0|655.32] "m/s"  EXXOTEST__XXX
 SG_ COG : 112|16@1+ (0.0001,0) [0|6.28318] "rad"  EXXOTEST__XXX
 SG_ TimeStamp : 106|6@1+ (1,0) [0|63] ""  EXXOTEST__XXX
 SG_ RAIMFlag : 105|1@1+ (1,0) [0|1] ""  EXXOTEST__XXX
 SG_ PosAccuracy : 104|1@1+ (1,0) [0|1] ""  EXXOTEST__XXX
 SG_ Latitude_ : 72|32@1- (1,0) [-90|90] "deg"  EXXOTEST__XXX
 SG_ Longitude_ : 40|32@1- (1,0) [-180|180] "deg"  EXXOTEST__XXX
 SG_ UserID : 8|32@1+ (1,0) [0|4294967292] ""  EXXOTEST__XXX
 SG_ RepeatIndicator : 6|2@1+ (1,0) [0|3] ""  EXXOTEST__XXX
 SG_ MsgID : 0|6@1+ (1,0) [0|63] ""  EXXOTEST__XXX

BO_ 2650475518 AISInterrogation: 25 EXXOTEST__XXX
 SG_ SlotOffset21 : 176|16@1+ (1,0) [0|65532] ""  EXXOTEST__XXX
 SG_ MsgID21 : 170|6@1+ (1,0) [0|63] ""  EXXOTEST__XXX
 SG_ DestinationID2 : 136|32@1+ (1,0) [0|4294967292] ""  EXXOTEST__XXX
 SG_ SlotOffset12 : 112|16@1+ (1,0) [0|65532] ""  EXXOTEST__XXX
 SG_ MsgID12 : 106|6@1+ (1,0) [0|63] ""  EXXOTEST__XXX
 SG_ SlotOffset11 : 88|16@1+ (1,0) [0|65532] ""  EXXOTEST__XXX
 SG_ MsgID11 : 82|6@1+ (1,0) [0|63] ""  EXXOTEST__XXX
 SG_ DestinationID1 : 48|32@1+ (1,0) [0|4294967292] ""  EXXOTEST__XXX
 SG_ AISTransceiverInformation : 41|5@1+ (1,0) [0|31] ""  EXXOTEST__XXX
 SG_ SourceID : 8|32@1+ (1,0) [0|4294967292] ""  EXXOTEST__XXX
 SG_ RepeatIndicator : 6|2@1+ (1,0) [0|3] ""  EXXOTEST__XXX
 SG_ MsgID : 0|6@1+ (1,0) [0|63] ""  EXXOTEST__XXX

BO_ 2650476030 AISDataLinkManagementMsg: 31 EXXOTEST__XXX
 SG_ Increment4 : 224|16@1+ (1,0) [0|65532] ""  EXXOTEST__XXX
 SG_ TimeOut4 : 216|8@1+ (1,0) [0|252] ""  EXXOTEST__XXX
 SG_ NumberOfSlots4 : 208|8@1+ (1,0) [0|252] ""  EXXOTEST__XXX
 SG_ OffsetNumber4 : 192|16@1+ (1,0) [0|65532] ""  EXXOTEST__XXX
 SG_ Increment3 : 176|16@1+ (1,0) [0|65532] ""  EXXOTEST__XXX
 SG_ TimeOut3 : 168|8@1+ (1,0) [0|252] ""  EXXOTEST__XXX
 SG_ NumberOfSlots3 : 160|8@1+ (1,0) [0|252] ""  EXXOTEST__XXX
 SG_ OffsetNumber3 : 144|16@1+ (1,0) [0|65532] ""  EXXOTEST__XXX
 SG_ Increment2 : 128|16@1+ (1,0) [0|65532] ""  EXXOTEST__XXX
 SG_ TimeOut2 : 120|8@1+ (1,0) [0|252] ""  EXXOTEST__XXX
 SG_ NumberOfSlots2 : 112|8@1+ (1,0) [0|252] ""  EXXOTEST__XXX
 SG_ OffsetNumber2 : 96|16@1+ (1,0) [0|65532] ""  EXXOTEST__XXX
 SG_ Increment1 : 80|16@1+ (1,0) [0|65532] ""  EXXOTEST__XXX
 SG_ TimeOut1 : 72|8@1+ (1,0) [0|252] ""  EXXOTEST__XXX
 SG_ NumberOfSlots1 : 64|8@1+ (1,0) [0|252] ""  EXXOTEST__XXX
 SG_ OffsetNumber1 : 48|16@1+ (1,0) [0|65532] ""  EXXOTEST__XXX
 SG_ AISTransceiverInformation : 41|5@1+ (1,0) [0|31] ""  EXXOTEST__XXX
 SG_ SourceStationID : 8|32@1+ (1,0) [0|4294967292] ""  EXXOTEST__XXX
 SG_ RepeatIndicator : 6|2@1+ (1,0) [0|3] ""  EXXOTEST__XXX
 SG_ MsgID : 0|6@1+ (1,0) [0|63] ""  EXXOTEST__XXX

BO_ 2583363838 AISDGNSSBroadcastBinaryMsg: 17 EXXOTEST__XXX
 SG_ NumberOfBitsInBinaryDataField : 120|16@1+ (1,0) [0|65532] ""  EXXOTEST__XXX
 SG_ Latitude_ : 80|32@1- (1,0) [-90|90] "deg"  EXXOTEST__XXX
 SG_ Longitude_ : 48|32@1- (1,0) [-180|180] "deg"  EXXOTEST__XXX
 SG_ AISTransceiverInformation : 41|5@1+ (1,0) [0|31] ""  EXXOTEST__XXX
 SG_ SourceID : 8|32@1+ (1,0) [0|4294967292] ""  EXXOTEST__XXX
 SG_ RepeatIndicator : 6|2@1+ (1,0) [0|3] ""  EXXOTEST__XXX
 SG_ MsgID : 0|6@1+ (1,0) [0|63] ""  EXXOTEST__XXX

BO_ 2650473214 AISClssASttcAndVyageRelatedData: 73 EXXOTEST__XXX
 SG_ Destination : 424|160@1+ (1,0) [0|255] "ASCII"  EXXOTEST__XXX
 SG_ Name : 128|160@1+ (1,0) [0|65535] "ASCII"  EXXOTEST__XXX
 SG_ CallSign : 72|56@1+ (1,0) [0|255] "ASCII"  EXXOTEST__XXX
 SG_ IMO : 40|32@1+ (1,0) [0|4294967292] ""  EXXOTEST__XXX
 SG_ UserID : 8|32@1+ (1,0) [0|4294967292] ""  EXXOTEST__XXX
 SG_ RepeatIndicator : 6|2@1+ (1,0) [0|3] ""  EXXOTEST__XXX
 SG_ MsgID : 0|6@1+ (1,0) [0|63] ""  EXXOTEST__XXX

BO_ 2448953342 AISClassBPosReport: 26 EXXOTEST__XXX
 SG_ ComminicationStateSelectorFlag : 200|1@1+ (1,0) [0|1] ""  EXXOTEST__XXX
 SG_ TrueHeading : 168|16@1+ (0.0001,0) [0|6.28318] "rad"  EXXOTEST__XXX
 SG_ AISTransceiverInformation : 163|5@1+ (1,0) [0|31] ""  EXXOTEST__XXX
 SG_ CommunicationState : 144|19@1+ (1,0) [0|524287] ""  EXXOTEST__XXX
 SG_ SOG : 128|16@1+ (0.01,0) [0|655.32] "m/s"  EXXOTEST__XXX
 SG_ COG : 112|16@1+ (0.0001,0) [0|6.28318] "rad"  EXXOTEST__XXX
 SG_ TimeStamp : 106|6@1+ (1,0) [0|63] ""  EXXOTEST__XXX
 SG_ RAIMflag : 105|1@1+ (1,0) [0|1] ""  EXXOTEST__XXX
 SG_ PosAccuracy : 104|1@1+ (1,0) [0|1] ""  EXXOTEST__XXX
 SG_ Latitude_ : 72|32@1- (1,0) [-90|90] "deg"  EXXOTEST__XXX
 SG_ Longitude_ : 40|32@1- (1,0) [-180|180] "deg"  EXXOTEST__XXX
 SG_ UserID : 8|32@1+ (1,0) [0|4294967292] ""  EXXOTEST__XXX
 SG_ RepeatIndicator : 6|2@1+ (1,0) [0|3] ""  EXXOTEST__XXX
 SG_ MsgID : 0|6@1+ (1,0) [0|63] ""  EXXOTEST__XXX

BO_ 2448953598 AISClassBExPosReport: 52 EXXOTEST__XXX
 SG_ Name : 256|160@1+ (1,0) [0|65535] "ASCII"  EXXOTEST__XXX
 SG_ PosReferencePointAftOfShipsBow : 240|16@1+ (0.1,0) [0|6553.2] "m"  EXXOTEST__XXX
 SG_ PosReferencePointFromStarboard : 224|16@1+ (0.1,0) [0|6553.2] "m"  EXXOTEST__XXX
 SG_ ShipBeam : 208|16@1+ (0.1,0) [0|6553.2] "m"  EXXOTEST__XXX
 SG_ ShipLength : 192|16@1+ (0.1,0) [0|6553.2] "m"  EXXOTEST__XXX
 SG_ TypeOfElectronicPosingDevice : 188|4@1+ (1,0) [0|15] ""  EXXOTEST__XXX
 SG_ TrueHeading : 168|16@1+ (0.0001,0) [0|6.28318] "rad"  EXXOTEST__XXX
 SG_ Ship_CargoType : 160|8@1+ (1,0) [0|255] ""  EXXOTEST__XXX
 SG_ SOG : 128|16@1+ (0.01,0) [0|655.32] "m/s"  EXXOTEST__XXX
 SG_ COG : 112|16@1+ (0.0001,0) [0|6.28318] "rad"  EXXOTEST__XXX
 SG_ TimeStamp : 106|6@1+ (1,0) [0|63] ""  EXXOTEST__XXX
 SG_ RAIMflag : 105|1@1+ (1,0) [0|1] ""  EXXOTEST__XXX
 SG_ PosAccuracy : 104|1@1+ (1,0) [0|1] ""  EXXOTEST__XXX
 SG_ Latitude_ : 72|32@1- (1,0) [-90|90] "deg"  EXXOTEST__XXX
 SG_ Longitude_ : 40|32@1- (1,0) [-180|180] "deg"  EXXOTEST__XXX
 SG_ UserID : 8|32@1+ (1,0) [0|4294967292] ""  EXXOTEST__XXX
 SG_ RepeatIndicator : 6|2@1+ (1,0) [0|3] ""  EXXOTEST__XXX
 SG_ MsgID : 0|6@1+ (1,0) [0|63] ""  EXXOTEST__XXX

BO_ 2566838526 CA: 9 EXXOTEST__XXX
 SG_ AddressAssignment : 64|8@1+ (1,0) [0|255] ""  EXXOTEST__XXX
 SG_ ArbitraryAddressCapable : 63|1@1+ (1,0) [0|1] ""  EXXOTEST__XXX
 SG_ IndustryGroup M : 60|3@1+ (1,0) [0|7] ""  EXXOTEST__XXX
 SG_ VehicleSystemInstance : 56|4@1+ (1,0) [0|15] ""  EXXOTEST__XXX
 SG_ Function : 40|8@1+ (1,0) [0|255] ""  EXXOTEST__XXX
 SG_ VehicleSystem m0 : 49|7@1+ (1,0) [0|127] ""  EXXOTEST__XXX
 SG_ FunctionInstance : 35|5@1+ (1,0) [0|31] ""  EXXOTEST__XXX
 SG_ ECUInstance : 32|3@1+ (1,0) [0|7] ""  EXXOTEST__XXX
 SG_ ManufacturerCode : 21|11@1+ (1,0) [0|2047] ""  EXXOTEST__XXX
 SG_ IdentityNumber : 0|21@1+ (1,0) [0|2097152] ""  EXXOTEST__XXX
 SG_ VehicleSystem5 m5 : 49|7@1+ (1,0) [0|127] ""  EXXOTEST__XXX
 SG_ VehicleSystem4 m4 : 49|7@1+ (1,0) [0|127] ""  EXXOTEST__XXX
 SG_ VehicleSystem3 m3 : 49|7@1+ (1,0) [0|127] ""  EXXOTEST__XXX
 SG_ VehicleSystem2 m2 : 49|7@1+ (1,0) [0|127] ""  EXXOTEST__XXX
 SG_ VehicleSystem1 m1 : 49|7@1+ (1,0) [0|127] ""  EXXOTEST__XXX

CM_ BO_ 2381842942 "This_PGN_has_a_single_transmission_that_provides:_-_UTC_Time_-_UTC_Date_-_Local_offset_Products_that_can_maintain_or_have_a_method_of_calculating_or_manually_providing_local_offset_should_transmit_this_PGN";
CM_ SG_ 2381842942 LocalOffsetMinutes "Local_time_zone_offset_in_minutes.__Local_time_zone_is_added_to_local_time_to_obtain_UTC.__Local_zone_is_generally_negative_for_East_longitudes,_with_local_exceptions_near_the_International_Date_Line.";
CM_ SG_ 2381842942 Time "24_hour_clock,_0_=__midnight,__time_is_in_UTC";
CM_ SG_ 2381842942 Date "Days_since_January_1,_1970,___Date_is_relative_to_UTC_Time.";
CM_ BO_ 2381911550 "Time_to_go_to_elapsed_from_a_generic_mark,that_may_be_non-fixedmark_is_not_generally_a_specific_geographic_point_but_may_vary_continuously_and_is_most_often_determined_by_calculationrecommended_turning_tacking_point_for_sailing_vessels,wheel-over_point_";
CM_ SG_ 2381911550 MarkID "Number_of_route,_waypoint,_event,_mark,_etc.";
CM_ SG_ 2381911550 MarkType "0___=_Collision,__1_=_Turning_Point,_2_=_Reference_(general),_3_=_Wheelover,_4_=_Waypoint,_5-13_=_Reserved,_14_=_Error,_15_=_Null";
CM_ SG_ 2381911550 TimeElapsedTogoToMark "Time_interval_in_milli-sec.__'-'__=_time_elapsed_since_event,_'+'_=_time_to_go_before_event.";
CM_ SG_ 2381911550 SID "An_upward_counting_number_used_to_tie_related_information_together_between_different_PGNs.For_example,SID_would_be_used_to_tie_together_COG,SOG_and_RAIM_values_to_a_given_Pos.255=no_valid_Pos_fix_to_tie_it_to.Range_0_to_250_for_valid_Pos_fixes.";
CM_ BO_ 2583499006 "Tide_station_measurement_data_including_station_location,_numeric_identifier,_and_name";
CM_ SG_ 2583499006 StationNameString "Name_of_place,_route,_waypoint,_destination,_vessel,_vehicle,_etc.";
CM_ SG_ 2583499006 StationIDString "Name_of_place,_route,_waypoint,_destination,_vessel,_vehicle,_etc.";
CM_ SG_ 2583499006 TideLevelStandardDeviation "following_text_is_from_NOAA_and_is_placed_here_to_convey_an_understanding_of_expected_magnitude_of_values.'tide_gage_processes_181_water_level_samples,1_second_apart,centered_on_6_minute_mark.It_then_computes_standard_deviation_of_Samples.Samples_more_tha";
CM_ SG_ 2583499006 TideLevel "This_value_is_relative_to_mean_lower_low_water_(MLLW).";
CM_ SG_ 2583499006 MeasurementTime "24_hour_clock,_0_=__midnight,__time_is_in_UTC";
CM_ SG_ 2583499006 MeasurementDate "Days_since_January_1,_1970,___Date_is_relative_to_UTC_Time.";
CM_ SG_ 2583499006 TideTendency "msb/lsb:__00_=_Falling,_01_=_Rising,_10_=_Error,_11_=_Unavailable,_Unknown";
CM_ SG_ 2583499006 Mode "Range_Residual_used_in_position_calculation_or_range_residuals_were_calculated_after_the_position.___0=range_residuals_were_used_to_calculate_dat";
CM_ BO_ 2381320446 "The_purpose_of_this_PGN_is_twofold:_-_To_provide_a_regular_transmission_of_UTC_time_and_date_-_To_provide_synchronism_for_measurement_data";
CM_ SG_ 2381320446 Time "24_hour_clock,_0_=__midnight,__time_is_in_UTC";
CM_ SG_ 2381320446 Date "Days_since_January_1,_1970,___Date_is_relative_to_UTC_Time.";
CM_ SG_ 2381320446 Source "0x0_=_GPS,__0x1_=GLONASS,_0x2_=_WWV_or_equivalent_Radio_Station_Time_Sync,_0x3_=_Local_Cesium_clock,_0x4_=_Local_Rubidium_clock,_0x5_=_Local_Crystal_clock,_0x6_-_0xE_=_reserved,_0xF_=_Null";
CM_ SG_ 2381320446 SID "An_upward_counting_number_used_to_tie_related_information_together_between_different_PGNs.For_example,SID_would_be_used_to_tie_together_COG,SOG_and_RAIM_values_to_a_given_Pos.255=no_valid_Pos_fix_to_tie_it_to.Range_0_to_250_for_valid_Pos_fixes.";
CM_ BO_ 2381451006 "Universal_commands_to_multiple_banks_of_two-state_devices";
CM_ SG_ 2381451006 Switch28 "00_=_[Turn_Off,_Disable,_Reset,_Make_'0'],_01_=_[Turn_On,_Enable,_Set,_Make_'1'],_02_=_Reserved,_03_=_No_action";
CM_ SG_ 2381451006 Switch27 "00_=_[Turn_Off,_Disable,_Reset,_Make_'0'],_01_=_[Turn_On,_Enable,_Set,_Make_'1'],_02_=_Reserved,_03_=_No_action";
CM_ SG_ 2381451006 Switch26 "00_=_[Turn_Off,_Disable,_Reset,_Make_'0'],_01_=_[Turn_On,_Enable,_Set,_Make_'1'],_02_=_Reserved,_03_=_No_action";
CM_ SG_ 2381451006 Switch25 "00_=_[Turn_Off,_Disable,_Reset,_Make_'0'],_01_=_[Turn_On,_Enable,_Set,_Make_'1'],_02_=_Reserved,_03_=_No_action";
CM_ SG_ 2381451006 Switch24 "00_=_[Turn_Off,_Disable,_Reset,_Make_'0'],_01_=_[Turn_On,_Enable,_Set,_Make_'1'],_02_=_Reserved,_03_=_No_action";
CM_ SG_ 2381451006 Switch23 "00_=_[Turn_Off,_Disable,_Reset,_Make_'0'],_01_=_[Turn_On,_Enable,_Set,_Make_'1'],_02_=_Reserved,_03_=_No_action";
CM_ SG_ 2381451006 Switch22 "00_=_[Turn_Off,_Disable,_Reset,_Make_'0'],_01_=_[Turn_On,_Enable,_Set,_Make_'1'],_02_=_Reserved,_03_=_No_action";
CM_ SG_ 2381451006 Switch21 "00_=_[Turn_Off,_Disable,_Reset,_Make_'0'],_01_=_[Turn_On,_Enable,_Set,_Make_'1'],_02_=_Reserved,_03_=_No_action";
CM_ SG_ 2381451006 Switch20 "00_=_[Turn_Off,_Disable,_Reset,_Make_'0'],_01_=_[Turn_On,_Enable,_Set,_Make_'1'],_02_=_Reserved,_03_=_No_action";
CM_ SG_ 2381451006 Switch19 "00_=_[Turn_Off,_Disable,_Reset,_Make_'0'],_01_=_[Turn_On,_Enable,_Set,_Make_'1'],_02_=_Reserved,_03_=_No_action";
CM_ SG_ 2381451006 Switch18 "00_=_[Turn_Off,_Disable,_Reset,_Make_'0'],_01_=_[Turn_On,_Enable,_Set,_Make_'1'],_02_=_Reserved,_03_=_No_action";
CM_ SG_ 2381451006 Switch17 "00_=_[Turn_Off,_Disable,_Reset,_Make_'0'],_01_=_[Turn_On,_Enable,_Set,_Make_'1'],_02_=_Reserved,_03_=_No_action";
CM_ SG_ 2381451006 Switch16 "00_=_[Turn_Off,_Disable,_Reset,_Make_'0'],_01_=_[Turn_On,_Enable,_Set,_Make_'1'],_02_=_Reserved,_03_=_No_action";
CM_ SG_ 2381451006 Switch15 "00_=_[Turn_Off,_Disable,_Reset,_Make_'0'],_01_=_[Turn_On,_Enable,_Set,_Make_'1'],_02_=_Reserved,_03_=_No_action";
CM_ SG_ 2381451006 Switch14 "00_=_[Turn_Off,_Disable,_Reset,_Make_'0'],_01_=_[Turn_On,_Enable,_Set,_Make_'1'],_02_=_Reserved,_03_=_No_action";
CM_ SG_ 2381451006 Switch13 "00_=_[Turn_Off,_Disable,_Reset,_Make_'0'],_01_=_[Turn_On,_Enable,_Set,_Make_'1'],_02_=_Reserved,_03_=_No_action";
CM_ SG_ 2381451006 Switch12 "00_=_[Turn_Off,_Disable,_Reset,_Make_'0'],_01_=_[Turn_On,_Enable,_Set,_Make_'1'],_02_=_Reserved,_03_=_No_action";
CM_ SG_ 2381451006 Switch11 "00_=_[Turn_Off,_Disable,_Reset,_Make_'0'],_01_=_[Turn_On,_Enable,_Set,_Make_'1'],_02_=_Reserved,_03_=_No_action";
CM_ SG_ 2381451006 Switch10 "00_=_[Turn_Off,_Disable,_Reset,_Make_'0'],_01_=_[Turn_On,_Enable,_Set,_Make_'1'],_02_=_Reserved,_03_=_No_action";
CM_ SG_ 2381451006 Switch9 "00_=_[Turn_Off,_Disable,_Reset,_Make_'0'],_01_=_[Turn_On,_Enable,_Set,_Make_'1'],_02_=_Reserved,_03_=_No_action";
CM_ SG_ 2381451006 Switch8 "00_=_[Turn_Off,_Disable,_Reset,_Make_'0'],_01_=_[Turn_On,_Enable,_Set,_Make_'1'],_02_=_Reserved,_03_=_No_action";
CM_ SG_ 2381451006 Switch7 "00_=_[Turn_Off,_Disable,_Reset,_Make_'0'],_01_=_[Turn_On,_Enable,_Set,_Make_'1'],_02_=_Reserved,_03_=_No_action";
CM_ SG_ 2381451006 Switch6 "00_=_[Turn_Off,_Disable,_Reset,_Make_'0'],_01_=_[Turn_On,_Enable,_Set,_Make_'1'],_02_=_Reserved,_03_=_No_action";
CM_ SG_ 2381451006 Switch5 "00_=_[Turn_Off,_Disable,_Reset,_Make_'0'],_01_=_[Turn_On,_Enable,_Set,_Make_'1'],_02_=_Reserved,_03_=_No_action";
CM_ SG_ 2381451006 Switch4 "00_=_[Turn_Off,_Disable,_Reset,_Make_'0'],_01_=_[Turn_On,_Enable,_Set,_Make_'1'],_02_=_Reserved,_03_=_No_action";
CM_ SG_ 2381451006 Switch3 "00_=_[Turn_Off,_Disable,_Reset,_Make_'0'],_01_=_[Turn_On,_Enable,_Set,_Make_'1'],_02_=_Reserved,_03_=_No_action";
CM_ SG_ 2381451006 Switch2 "00_=_[Turn_Off,_Disable,_Reset,_Make_'0'],_01_=_[Turn_On,_Enable,_Set,_Make_'1'],_02_=_Reserved,_03_=_No_action";
CM_ SG_ 2381451006 Switch1 "00_=_[Turn_Off,_Disable,_Reset,_Make_'0'],_01_=_[Turn_On,_Enable,_Set,_Make_'1'],_02_=_Reserved,_03_=_No_action";
CM_ SG_ 2381451006 SwitchBankInstance "Number_of_route,_waypoint,_event,_mark,_etc.";
CM_ BO_ 2314535934 "The_purpose_of_this_PGN_is_to_provide_a_single_transmission_that_describes_the_motion_of_a_vessel";
CM_ SG_ 2314535934 SequenceID_ "An_upward_counting_number_used_to_tie_related_information_together_between_different_PGNs.For_example,SID_would_be_used_to_tie_together_COG,SOG_and_RAIM_values_to_a_given_Pos.255=no_valid_Pos_fix_to_tie_it_to.Range_0_to_250_for_valid_Pos_fixes.";
CM_ BO_ 2315129086 "Provides_data_on_various_small_craft_control_surfaces_and_speed_through_the_water_Used_primarily_by_display_or_instrumentation_devices";
CM_ BO_ 2381908990 "Set_and_Drift_effect_on_Vessel_is_direction_and_speed_of__a_currentCourse&Speedthrough_watervector_added_to_Set&Drift_vector_is_COG&SOG_vectorbearings_may_be_True_Magnetic_referenced_When_Set&Drift_is_calculated_from_data_from_a_GPS,a_compass_and_a_";
CM_ SG_ 2381908990 Set "Direction_towards_which_current_flows.__Degrees_relative_to_True_North.";
CM_ SG_ 2381908990 SetReference "0_=_True,__1_=_Magnetic,_2_=_Error,_3_=_Null";
CM_ SG_ 2381908990 SID "An_upward_counting_number_used_to_tie_related_information_together_between_different_PGNs.For_example,SID_would_be_used_to_tie_together_COG,SOG_and_RAIM_values_to_a_given_Pos.255=no_valid_Pos_fix_to_tie_it_to.Range_0_to_250_for_valid_Pos_fixes.";
CM_ BO_ 2583499262 "Salinity_station_measurement_data_including_station_location,_numeric_identifier,_and_name";
CM_ BO_ 2650543102 "Complex_Rq_of_this_PGN_should_return_Waypoints_belonging_to_a_Route_WARNING:Route_Track_may_not_be_defined_by_Waypoint_Poss_only:Navigation_MethodGC/RLand_Radius_of_Turn_at_each_Waypoint_are_optional_additional_parameters_defining_Track_PGN_130066";
CM_ SG_ 2650543102 WPName "Name_of_place,_route,_waypoint,_destination,_vessel,_vehicle,_etc.";
CM_ SG_ 2650543102 WPID "Number_of_route,_waypoint,_event,_mark,_etc.";
CM_ SG_ 2650543102 RouteID "Number_of_route,_waypoint,_event,_mark,_etc.";
CM_ SG_ 2650543102 DatabaseID "Number_of_route,_waypoint,_event,_mark,_etc.";
CM_ SG_ 2650543102 NumberOfWPsInRoute "Number_of_route,_waypoint,_event,_mark,_etc.";
CM_ SG_ 2650543102 nItems "Number_of_route,_waypoint,_event,_mark,_etc.";
CM_ SG_ 2650543102 StartRPS "Number_of_route,_waypoint,_event,_mark,_etc.";
CM_ BO_ 2650543358 "Complex_Rq_of_this_PGN_should_return_Waypoints_belonging_to_a_Route_WARNING:Route_Track_may_not_be_defined_by_Waypoint_Poss_only:Navigation_MethodGC/RLand_Radius_of_Turn_at_each_Waypoint_are_optional_additional_parameters_defining_Track_PGN_130066";
CM_ SG_ 2650543358 WPName "Name_of_place,_route,_waypoint,_destination,_vessel,_vehicle,_etc.";
CM_ SG_ 2650543358 WPID "Number_of_route,_waypoint,_event,_mark,_etc.";
CM_ SG_ 2650543358 RouteID "Number_of_route,_waypoint,_event,_mark,_etc.";
CM_ SG_ 2650543358 DatabaseID "Number_of_route,_waypoint,_event,_mark,_etc.";
CM_ SG_ 2650543358 NumberOfWPsInRoute "Number_of_route,_waypoint,_event,_mark,_etc.";
CM_ SG_ 2650543358 nItems "Number_of_route,_waypoint,_event,_mark,_etc.";
CM_ SG_ 2650543358 StartRPS "Number_of_route,_waypoint,_event,_mark,_etc.";
CM_ BO_ 2650542590 "Complex_Rq_for_this_PGN_should_return_a_list_of_Routes_in_a_Database_A_Database_may_contain_Routes_identified_with_Route_ID_in_range_0-65532There_may_be_empty_gapsRoute_ID_does_not_represent_a_valid/existent_Routeanywhere_in_this_rangeThis_PGN_sha";
CM_ SG_ 2650542590 RouteName "Name_of_place,_route,_waypoint,_destination,_vessel,_vehicle,_etc.";
CM_ SG_ 2650542590 RouteID "Number_of_route,_waypoint,_event,_mark,_etc.";
CM_ SG_ 2650542590 DatabaseID "Number_of_route,_waypoint,_event,_mark,_etc.";
CM_ SG_ 2650542590 NmbrOfRoutesAvailableInDatabase "Number_of_route,_waypoint,_event,_mark,_etc.";
CM_ SG_ 2650542590 nItems "Number_of_route,_waypoint,_event,_mark,_etc.";
CM_ SG_ 2650542590 StartRouteID "Number_of_route,_waypoint,_event,_mark,_etc.";
CM_ BO_ 2650544126 "Complex_Rq_of_this_PGN_should_return_supplementary_Comments_attached_to_Routes_Database_ID_shall_be_specified_in_Rq/reply_Routes_without_a_comment_shall_not_be_included_in_this_PGN_reply_should_use_same_transfer_Protcl_as_Rq_ISO_Rq_for_this_PG";
CM_ SG_ 2650544126 RouteID "Number_of_route,_waypoint,_event,_mark,_etc.";
CM_ SG_ 2650544126 DatabaseID "Number_of_route,_waypoint,_event,_mark,_etc.";
CM_ SG_ 2650544126 NumberOfRoutesWithComments "Number_of_route,_waypoint,_event,_mark,_etc.";
CM_ SG_ 2650544126 nItems "Number_of_route,_waypoint,_event,_mark,_etc.";
CM_ SG_ 2650544126 StartRouteID "Number_of_route,_waypoint,_event,_mark,_etc.";
CM_ BO_ 2650544638 "Complex_Rq_of_this_PGN_should_return_Radius_of_Turn_at_specific_Waypoints_of_a_Route_For_a_complete_description_of_Route_and_WP_PGNs,see_App_note_in_Appendix_DRadius_of_Turn_is_described_in_Appendix_D5156_Database_ID_and_Route_ID_shall_be_spec";
CM_ SG_ 2650544638 RadiusOfTurn "A_commanded_distance_like_radius_order,_off-track_limit,_etc.";
CM_ SG_ 2650544638 RPS "Number_of_route,_waypoint,_event,_mark,_etc.";
CM_ SG_ 2650544638 RouteID "Number_of_route,_waypoint,_event,_mark,_etc.";
CM_ SG_ 2650544638 DatabaseID "Number_of_route,_waypoint,_event,_mark,_etc.";
CM_ SG_ 2650544638 NmbrOfWypntsWthASpcfcRdusOfTurn "Number_of_route,_waypoint,_event,_mark,_etc.";
CM_ SG_ 2650544638 nItems "Number_of_route,_waypoint,_event,_mark,_etc.";
CM_ SG_ 2650544638 StartRPS "Number_of_route,_waypoint,_event,_mark,_etc.";
CM_ BO_ 2650542334 "Complex_Rq_for_this_PGN_should_return_a_list_of_Databases_in_which_a_navigation_Deviceganizes_its_Routes_and_WPs_A_Database_may_contain_one_WP-List_and_multiple_Routes_A_device_need_not_support_concept_of_multiple_Databasessupport_of_this_PGN_is_";
CM_ SG_ 2650542334 DatabaseName "Name_of_place,_route,_waypoint,_destination,_vessel,_vehicle,_etc.";
CM_ SG_ 2650542334 DatabaseID "Number_of_route,_waypoint,_event,_mark,_etc.";
CM_ SG_ 2650542334 NumberOfDatabasesAvailable "Number_of_route,_waypoint,_event,_mark,_etc.";
CM_ SG_ 2650542334 nItems "Number_of_route,_waypoint,_event,_mark,_etc.";
CM_ SG_ 2650542334 StartDatabaseID "Number_of_route,_waypoint,_event,_mark,_etc.";
CM_ BO_ 2314277886 "Rate_of_Turn_is_the_rate_of_change_of_the_Heading_Heading_is_defined_as_the_direction_of_the_vertical_projection_of_the_fore-and-aft_line_of_the_ship_onto_the_horizontal_plane";
CM_ SG_ 2314277886 RateOfTurn "+_=_Bow_turning_to_starboard,_1_deg/min_=_.00029_rad/sec";
CM_ SG_ 2314277886 SequenceID_ "An_upward_counting_number_used_to_tie_related_information_together_between_different_PGNs.For_example,SID_would_be_used_to_tie_together_COG,SOG_and_RAIM_values_to_a_given_Pos.255=no_valid_Pos_fix_to_tie_it_to.Range_0_to_250_for_valid_Pos_fixes.";
CM_ BO_ 2382039038 "This_PGN_provides_status_and_control_for_a_Radiotelephone,_connected_to_a_NMEA_2000_network_The_Radiotelephone_will_transmit_and_receive_status_along_with_remote_control_and_repeater_products";
CM_ SG_ 2382039038 RadioChannel "MF/HF_telephone_channels_to_have_first_digit_3_followed_by_ITU_channel_numbers_with_leading_zeros_as_required.MF/HF_teletype_channels_to_have_first_digit_4_second_and_third_digit_give_frequency_bands_and_fourth_to_sixth_digits_ITU_channel_numbers_each_";
CM_ BO_ 2314732542 "ThePos_Delta,High_Precision_Rapid_UpdateParameter_Group_is_intended_for_Apps_where_very_high_precision_and_very_fast_update_rates_are_needed_for_Pos_dataThis_PG_can_provide_delta_Pos_changes_down_to_1_millimeter_with_a_delta_time_period_accurate_to_5_m";
CM_ SG_ 2314732542 SequenceID_ "An_upward_counting_number_used_to_tie_related_information_together_between_different_PGNs.For_example,SID_would_be_used_to_tie_together_COG,SOG_and_RAIM_values_to_a_given_Pos.255=no_valid_Pos_fix_to_tie_it_to.Range_0_to_250_for_valid_Pos_fixes.";
CM_ BO_ 2314732030 "This_PGN_provides_latitude_and_longitude_referenced_to_WGS84Being_defined_as_single_frame_Msg,as_opposed_to_other_PGNs_that_include_latitude_and_longitude_and_are_defined_as_fast_multi-packet,this_PGN_lends_itself_to_being_transmitted_more_frequently_wit";
CM_ BO_ 2583234046 "This_PGN_shall_return_Route_and_WP_data_ahead_in_Active_Route_It_can_be_Rqed_may_be_transmitted_without_a_Rq,typically_at_each_Waypoint_advance_When_navigating_Route_in_Forward_direction,Waypoints_shall_be_included_inder_of_increasing_RPSsWhen_na";
CM_ SG_ 2583234046 WPName "Name_of_place,_route,_waypoint,_destination,_vessel,_vehicle,_etc.";
CM_ SG_ 2583234046 RouteName "Name_of_place,_route,_waypoint,_destination,_vessel,_vehicle,_etc.";
CM_ SG_ 2583234046 SpplmntaryRoute_WPDataAvailable "MSB/LSB:__00_=_[No,_Off,_Disabled,_Reset,_'0'],_01_=_[Yes,_On,_Enabled,_Set,_'1'],_10_=_Error,_11=_[Unavailable,_Unknown]";
CM_ SG_ 2583234046 NavigationDirectionInRoute "0=Forward,__1=Reverse,_2-5_Reserved,_6=_Error,_7=Null_(info_not_available)";
CM_ SG_ 2583234046 RouteID "Number_of_route,_waypoint,_event,_mark,_etc.";
CM_ SG_ 2583234046 DatabaseID "Number_of_route,_waypoint,_event,_mark,_etc.";
CM_ SG_ 2583234046 nItems "Number_of_route,_waypoint,_event,_mark,_etc.";
CM_ SG_ 2583234046 StartRPS "Number_of_route,_waypoint,_event,_mark,_etc.";
CM_ BO_ 2381907198 "This_PGN_provides_essential_navigation_data_for_following_a_route_Transmissions_will_originate_from_products_that_can_create_and_manage_routes_using_waypoints_This_information_is_intended_for_navigational_repeaters";
CM_ SG_ 2381907198 WaypointClosingVelocity "Positive_values_represent_ahead_or_starboard_transverse_speed_and_negative_values_represent_astern_or_port_transverse_speed.";
CM_ SG_ 2381907198 DestinationWaypointNumber "Number_of_route,_waypoint,_event,_mark,_etc.";
CM_ SG_ 2381907198 OriginWaypointNumber "Number_of_route,_waypoint,_event,_mark,_etc.";
CM_ SG_ 2381907198 BearingPosToDestinationWaypoint "The_horizontal_direction_of_one_terrestrial_point_from_another,_expressed_as_the_angular_distance_from_a_reference_direction,_measured_from_000_at_the_reference_direction_clockwise_through_359_degrees.";
CM_ SG_ 2381907198 BaringiginToDestinationWaypoint "The_horizontal_direction_of_one_terrestrial_point_from_another,_expressed_as_the_angular_distance_from_a_reference_direction,_measured_from_000_at_the_reference_direction_clockwise_through_359_degrees.";
CM_ SG_ 2381907198 ETADate "Days_since_January_1,_1970,___Date_is_relative_to_UTC_Time.";
CM_ SG_ 2381907198 ETATime "24_hour_clock,_0_=__midnight,__time_is_in_UTC";
CM_ SG_ 2381907198 CalculationType "0_=_Great_Circle_calculations,__1_=_Rhumb_Line_calculations,_2_=_Error,_3_=_Null";
CM_ SG_ 2381907198 ArrivalCircleEntered "MSB/LSB:__00_=_[No,_Off,_Disabled,_Reset,_'0'],_01_=_[Yes,_On,_Enabled,_Set,_'1'],_10_=_Error,_11=_[Unavailable,_Unknown]";
CM_ SG_ 2381907198 PerpendicularCrossed "MSB/LSB:__00_=_[No,_Off,_Disabled,_Reset,_'0'],_01_=_[Yes,_On,_Enabled,_Set,_'1'],_10_=_Error,_11=_[Unavailable,_Unknown]";
CM_ SG_ 2381907198 Course_BearingRef "0_=_True,__1_=_Magnetic,_2_=_Error,_3_=_Null";
CM_ SG_ 2381907198 SID "An_upward_counting_number_used_to_tie_related_information_together_between_different_PGNs.For_example,SID_would_be_used_to_tie_together_COG,SOG_and_RAIM_values_to_a_given_Pos.255=no_valid_Pos_fix_to_tie_it_to.Range_0_to_250_for_valid_Pos_fixes.";
CM_ BO_ 2381184766 "Rq/Cmd/Acknowledge_Group_type_of_function_is_defined_by_first_fieldMsg_will_be_a_Rq,Cmd,or_Acknowledge_Group_FunctionThese_are_defined_as_follows:_Rq_Group_Function:This_Msg_Rqs_Trans_of_a_specific_set_of_data_in_a_Parameter_Group_by_setting_variable";
CM_ SG_ 2381184766 NumberOfRqedCmdedParameters "Numeric_count,_event_counter,_sequence_counter";
CM_ SG_ 2381184766 VrblNmbrOfFldsFldNmber6Repeated3 "0x0_=_No_Error/Acknowledge_";
CM_ SG_ 2381184766 FirstParameterErrorCode "0x0_=_No_Error/Acknowledge_";
CM_ SG_ 2381184766 TransInterval_PriorityErrorCode "0x0_=_No_Error/Acknowledge,__0x1_=_Transmit_Interval_/Priority_not_supported,_0x2_=_Transmit_interval_is_less_than_measurement/calculation_interval,_0x3_=_Access_denied._0x4_=_Request_is_not_supported.";
CM_ SG_ 2381184766 RqedCmdedPGNBeingAcknowledged "24-bit_Parameter_Group_Number_(PGN)_expressed_in_binary,_LSB_is_transmitted_first";
CM_ SG_ 2381184766 PGNErrorCode "0x0_=_No_Error/Acknowledge,__0x1_=_PGN_not_supported,_0x2_=_PGN_temporarily_not_available,_0x3_=_Access_denied,_0x4_=_Request_is_not_supported.";
CM_ SG_ 2381184766 VrblNmbrOfFldsFldNmber6Repeated2 "Number_of_route,_waypoint,_event,_mark,_etc.";
CM_ SG_ 2381184766 FeldNumberOfFirstCmdedParameter "Number_of_route,_waypoint,_event,_mark,_etc.";
CM_ SG_ 2381184766 NmbrOfPrsOfCmddPrmetersToFollow "Numeric_count,_event_counter,_sequence_counter";
CM_ SG_ 2381184766 PrioritySetting "0x0_to_0x7_=_commanded_priority_value_";
CM_ SG_ 2381184766 CmdedPGN "24-bit_Parameter_Group_Number_(PGN)_expressed_in_binary,_LSB_is_transmitted_first";
CM_ SG_ 2381184766 VrblNmbrOfFldsFldNmber6Repeated "Number_of_route,_waypoint,_event,_mark,_etc.";
CM_ SG_ 2381184766 FieldNumberOfFirstRqedParameter "Number_of_route,_waypoint,_event,_mark,_etc.";
CM_ SG_ 2381184766 NmbrOfPrsOfRqParametersToFollow "Numeric_count,_event_counter,_sequence_counter";
CM_ SG_ 2381184766 TransIntervalOffset "Offset_in_transmit_time_from_time_of_request_command:_0x0_=_transmit_immediately,_0xFFFF_=_Do_not_change_offset.";
CM_ SG_ 2381184766 TransInterval "Time_interval_between_data_transmissions:_0x0_=_Turn-off_transmission__0xFFFF_FFFF_=_Do_not_change_interval";
CM_ SG_ 2381184766 RqedPGN "24-bit_Parameter_Group_Number_(PGN)_expressed_in_binary,_LSB_is_transmitted_first";
CM_ SG_ 2381184766 GroupFunctionRq_Cmd_Acknowledge "0_=_Request_Message,__1_=_Command_Message,_2_=_Acknowledge_Message";
CM_ BO_ 2583500030 "Moored_buoy_measurement_data_including_station_location_and_numeric_identifier";
CM_ SG_ 2583500030 StationIDString "Name_of_place,_route,_waypoint,_destination,_vessel,_vehicle,_etc.";
CM_ SG_ 2583500030 PressTendencyRate "Positive_value_indicates_Rising,_Negative_value_indicates_Falling.";
CM_ SG_ 2583500030 DominateWavePeriod "Average_wave_period_of_all_waves_during_a_20-minute_period._Dominant_wave_period_is_the_period_with_the_maximum_wave_energy.__Note:_See_DD50_note.";
CM_ SG_ 2583500030 WaveHeight "Wave_height_is_calculated_as_highest_one-third_of_all_of_wave_heights_during_a_20-minute_sampling_period.Note:Accelerometers_inclinometers_on_board_buoys_measure_heave_acceleration_vertical_displacement_of_buoy_hull_during_wave_acquisition_time.A_Fast_Fou";
CM_ SG_ 2583500030 WindGusts "Peak_wind_gust_speed.__Sustained_wind_over_an_interval_of_5_seconds.";
CM_ SG_ 2583500030 WindReference "0x00_=_True_(referenced_to_North)_0x01_=_Magnetic_0x02_=_Apparent_0x03_=_True_(boat_referenced)_0x04_=_Reserved_0x05_=_Reserved_0x06_=_Error_0x07_=_Null";
CM_ SG_ 2583500030 MeasurementTime "24_hour_clock,_0_=__midnight,__time_is_in_UTC";
CM_ SG_ 2583500030 MeasurementDate "Days_since_January_1,_1970,___Date_is_relative_to_UTC_Time.";
CM_ SG_ 2583500030 Mode "Range_Residual_used_in_position_calculation_or_range_residuals_were_calculated_after_the_position.___0=range_residuals_were_used_to_calculate_dat";
CM_ BO_ 2583499774 "Meteorological_station_measurement_data_including_station_location,_numeric_identifier,_and_name";
CM_ SG_ 2583499774 StationNameString "Name_of_place,_route,_waypoint,_destination,_vessel,_vehicle,_etc.";
CM_ SG_ 2583499774 StationIDString "Name_of_place,_route,_waypoint,_destination,_vessel,_vehicle,_etc.";
CM_ SG_ 2583499774 WindGusts "Peak_wind_gust_speed.__Sustained_wind_over_an_interval_of_5_seconds.";
CM_ SG_ 2583499774 WindReference "0x00_=_True_(referenced_to_North)_0x01_=_Magnetic_0x02_=_Apparent_0x03_=_True_(boat_referenced)_0x04_=_Reserved_0x05_=_Reserved_0x06_=_Error_0x07_=_Null";
CM_ SG_ 2583499774 MeasurementTime "24_hour_clock,_0_=__midnight,__time_is_in_UTC";
CM_ SG_ 2583499774 MeasurementDate "Days_since_January_1,_1970,___Date_is_relative_to_UTC_Time.";
CM_ SG_ 2583499774 Mode "Range_Residual_used_in_position_calculation_or_range_residuals_were_calculated_after_the_position.___0=range_residuals_were_used_to_calculate_dat";
CM_ BO_ 2649823998 "Msg_for_transmitting_variationMsg_contains_a_sequence_number_to_allow_synchronization_of_other_Msgs_such_as_Heading_Course_over_Groundquality_of_service_and_age_of_service_are_provided_to_enable_recipients_to_determine_an_appropriate_level_of_service_if";
CM_ SG_ 2649823998 Variation "Positive_values_are_Easterly_and_negative_values_are_Westerly.";
CM_ SG_ 2649823998 AgeOfService "Days_since_January_1,_1970,___Date_is_relative_to_UTC_Time.";
CM_ SG_ 2649823998 VariationSource "0x00_=_Manual_Entry,_0x01_=_Automatic-Chart,_0x02_=_Automatic_Table,_0x03_=_Automatic_Calculation,_0x04_=_WMM_2000,_0x05_=_WMM_2005,_0x06_=_WMM_2010,_0x07_=_WMM_2015,_0x08_=_WMM_2020,_0x09_=_Reserve,_thru_0x3E_=_Reserve,_0x3F_=_Data_Not_Avail";
CM_ SG_ 2649823998 SequenceID_ "An_upward_counting_number_used_to_tie_related_information_together_between_different_PGNs.For_example,SID_would_be_used_to_tie_together_COG,SOG_and_RAIM_values_to_a_given_Pos.255=no_valid_Pos_fix_to_tie_it_to.Range_0_to_250_for_valid_Pos_fixes.";
CM_ BO_ 2382103806 "This_provides_Time_DifferenceTDlines_of_Pos_of_Loran-C_signals_relative_to_a_single_Group_Repetition_Interval_Field_1,Group_Repetition_IntervalGRI,is_identified_as_a_Rq_parameter_for_this_Parameter_GroupAll_providers_of_this_PGN_shall_accept_and";
CM_ SG_ 2382103806 Mode "Range_Residual_used_in_position_calculation_or_range_residuals_were_calculated_after_the_position.___0=range_residuals_were_used_to_calculate_dat";
CM_ SG_ 2382103806 StationStatusZ "MSB:_to_LSB:_xxx1_=_Station_in_use,_xx1x_=_Low_SNR,_x1xx_=_Cycle_error,_1xxx_=_Blink_where_x_=_don't_care";
CM_ SG_ 2382103806 StationStatusY "MSB:_to_LSB:_xxx1_=_Station_in_use,_xx1x_=_Low_SNR,_x1xx_=_Cycle_error,_1xxx_=_Blink_where_x_=_don't_care";
CM_ SG_ 2382103806 StationStatusX "MSB:_to_LSB:_xxx1_=_Station_in_use,_xx1x_=_Low_SNR,_x1xx_=_Cycle_error,_1xxx_=_Blink_where_x_=_don't_care";
CM_ SG_ 2382103806 StationStatusW "MSB:_to_LSB:_xxx1_=_Station_in_use,_xx1x_=_Low_SNR,_x1xx_=_Cycle_error,_1xxx_=_Blink_where_x_=_don't_care";
CM_ SG_ 2382103806 StationStatusV "MSB:_to_LSB:_xxx1_=_Station_in_use,_xx1x_=_Low_SNR,_x1xx_=_Cycle_error,_1xxx_=_Blink_where_x_=_don't_care";
CM_ SG_ 2382103806 StationStatusMaster "MSB:_to_LSB:_xxx1_=_Station_in_use,_xx1x_=_Low_SNR,_x1xx_=_Cycle_error,_1xxx_=_Blink_where_x_=_don't_care";
CM_ SG_ 2382103806 ZSecondTD "Loran-C_Time_difference_(TD)_in_nano-sec.__The_arrival_time_of_a_Loran-C_secondary_station_signal_minus_the_arrival_time_of_the_master_station_signal.";
CM_ SG_ 2382103806 YSecondTD "Loran-C_Time_difference_(TD)_in_nano-sec.__The_arrival_time_of_a_Loran-C_secondary_station_signal_minus_the_arrival_time_of_the_master_station_signal.";
CM_ SG_ 2382103806 XSecondTD "Loran-C_Time_difference_(TD)_in_nano-sec.__The_arrival_time_of_a_Loran-C_secondary_station_signal_minus_the_arrival_time_of_the_master_station_signal.";
CM_ SG_ 2382103806 WSecondTD "Loran-C_Time_difference_(TD)_in_nano-sec.__The_arrival_time_of_a_Loran-C_secondary_station_signal_minus_the_arrival_time_of_the_master_station_signal.";
CM_ SG_ 2382103806 VSecondTD "Loran-C_Time_difference_(TD)_in_nano-sec.__The_arrival_time_of_a_Loran-C_secondary_station_signal_minus_the_arrival_time_of_the_master_station_signal.";
CM_ SG_ 2382103806 MasterRange "The_actual_propagation_time_of_a_Loran-C_signal_from_the_station_to_a_receiver_in_nano-sec.";
CM_ SG_ 2382103806 GroupRepetitionInterval "Group_Repetition_Interval_(GRI)_in_nano-sec.__Often_cited_in_units_of_10_micro-sec._(i.e.,_9960_=_99,600,000_ns)";
CM_ BO_ 2382104318 "SNR,ECD,and_ASF_values_of_Loran-C_signals_Field_1,Group_Repetition_IntervalGRI,is_identified_as_a_Rq_parameter_for_this_Parameter_GroupAll_providers_of_this_PGN_shall_accept_and_process_Rqs_based_upon_Rqed_value_of_Field_1A_device_receiving_an_IS";
CM_ SG_ 2382104318 StationIdentifier "1-character_code_for_the_Loran-C_station:_M_=_master,_V,_W,_X,_Y,_Z";
CM_ SG_ 2382104318 GroupRepetitionInterval "Group_Repetition_Interval_(GRI)_in_nano-sec.__Often_cited_in_units_of_10_micro-sec._(i.e.,_9960_=_99,600,000_ns)";
CM_ BO_ 2382104062 "This_provides_Propagation_timesRangesof_Loran-C_signals_relative_to_a_single_Group_Repetition_Interval_Field_1,Group_Repetition_IntervalGRI,is_identified_as_a_Rq_parameter_for_this_Parameter_GroupAll_providers_of_this_PGN_shall_accept_and_proces";
CM_ SG_ 2382104062 Mode "Range_Residual_used_in_position_calculation_or_range_residuals_were_calculated_after_the_position.___0=range_residuals_were_used_to_calculate_dat";
CM_ SG_ 2382104062 StationStatusZ "MSB:_to_LSB:_xxx1_=_Station_in_use,_xx1x_=_Low_SNR,_x1xx_=_Cycle_error,_1xxx_=_Blink_where_x_=_don't_care";
CM_ SG_ 2382104062 StationStatusY "MSB:_to_LSB:_xxx1_=_Station_in_use,_xx1x_=_Low_SNR,_x1xx_=_Cycle_error,_1xxx_=_Blink_where_x_=_don't_care";
CM_ SG_ 2382104062 StationStatusX "MSB:_to_LSB:_xxx1_=_Station_in_use,_xx1x_=_Low_SNR,_x1xx_=_Cycle_error,_1xxx_=_Blink_where_x_=_don't_care";
CM_ SG_ 2382104062 StationStatusW "MSB:_to_LSB:_xxx1_=_Station_in_use,_xx1x_=_Low_SNR,_x1xx_=_Cycle_error,_1xxx_=_Blink_where_x_=_don't_care";
CM_ SG_ 2382104062 StationStatusV "MSB:_to_LSB:_xxx1_=_Station_in_use,_xx1x_=_Low_SNR,_x1xx_=_Cycle_error,_1xxx_=_Blink_where_x_=_don't_care";
CM_ SG_ 2382104062 StationStatusMaster "MSB:_to_LSB:_xxx1_=_Station_in_use,_xx1x_=_Low_SNR,_x1xx_=_Cycle_error,_1xxx_=_Blink_where_x_=_don't_care";
CM_ SG_ 2382104062 ZSecondRange "The_actual_propagation_time_of_a_Loran-C_signal_from_the_station_to_a_receiver_in_nano-sec.";
CM_ SG_ 2382104062 YSecondRange "The_actual_propagation_time_of_a_Loran-C_signal_from_the_station_to_a_receiver_in_nano-sec.";
CM_ SG_ 2382104062 XSecondRange "The_actual_propagation_time_of_a_Loran-C_signal_from_the_station_to_a_receiver_in_nano-sec.";
CM_ SG_ 2382104062 WSecondRange "The_actual_propagation_time_of_a_Loran-C_signal_from_the_station_to_a_receiver_in_nano-sec.";
CM_ SG_ 2382104062 VSecondRange "The_actual_propagation_time_of_a_Loran-C_signal_from_the_station_to_a_receiver_in_nano-sec.";
CM_ SG_ 2382104062 MasterRange "The_actual_propagation_time_of_a_Loran-C_signal_from_the_station_to_a_receiver_in_nano-sec.";
CM_ SG_ 2382104062 GroupRepetitionInterval "Group_Repetition_Interval_(GRI)_in_nano-sec.__Often_cited_in_units_of_10_micro-sec._(i.e.,_9960_=_99,600,000_ns)";
CM_ BO_ 2314274302 "Sends_Cmds_to,and_receives_data_from,heading_Ctrl_systemsAllows_for_navigationalremoteCtrl_of_a_heading_Ctrl_system_and_direct_rudder_CtrlWhen_used_as_a_Cmd,Cmded_Rudder_Direction_field_and_Cmded_Rudder_Angle_should_never_containder_values_at_same_tim";
CM_ SG_ 2314274302 VesselHeading "The_horizontal_direction_in_which_a_ship_actually_points_or_heads_at_any_instant,_expressed_in_angular_units_from_a_reference_direction,_usually_from_000_at_the_reference_direction_clockwise_through_359_degrees.";
CM_ SG_ 2314274302 OffTrackLimit "A_commanded_distance_like_radius_order,_off-track_limit,_etc.";
CM_ SG_ 2314274302 RateOfTurnder "+_=_Bow_turning_to_starboard,_1_deg/min_=_.00029_rad/sec";
CM_ SG_ 2314274302 RadiusOfTurnder "A_commanded_distance_like_radius_order,_off-track_limit,_etc.";
CM_ SG_ 2314274302 Track "intended_desired_horizontal_direction_of_travel_with_respect_to_earth.track_expressed_in_degrees_of_compass_may_differ_from_course_due_to_allowances_made_in_course_for_such_factors_as_sea_and_weather_conditions_inder_to_achieve_desired_track.This_field_re";
CM_ SG_ 2314274302 HeadingToSteer "The_horizontal_direction_in_which_a_vessel_is_steered_or_intended_to_be_steered,_expressed_as_angular_distance_000_north,_clockwise_through_359_degrees.__Not_to_be_confused_with_Course-over-ground,_Track,_or_Heading.";
CM_ SG_ 2314274302 CmdedRudderAngle "Rudder_angle_where_positive_values_are_starboard_and_negative_values_are_port";
CM_ SG_ 2314274302 CmdedRudderDirection "MSB/LSB:__000_=_No_Order,_001_=_Move_to_starboard,_010_=_Move_to_port.";
CM_ SG_ 2314274302 HeadingReference "0_=_True,__1_=_Magnetic,_2_=_Error,_3_=_Null";
CM_ SG_ 2314274302 TurnMode "MSB/LSB:_000_=_Rudder_Limit_Ctrlled,_001_=_turn_rate_Ctrlled,_010_=_radius_Ctrlled._Definitions:Rudder_–_An_operator_set_rudder_limit_determines_Max_turning_capability_available,in_which_case_system_outputs_rudderders_up_to_and_limited_by_rudder_limit";
CM_ SG_ 2314274302 SteerMode "MSB/LSB:_000_=_Main_Steer,_001_=_Non-Follow-up_Device,_010_=_Follow-up_Device,_011_=_Heading_Ctrl_Standalone,_100_=_Heading_Ctrl,_101_=_Track_Ctrl._Definitions:Main_Steer/Outside_System_–_main_Steer_system_is_in_use._Non-Follow-up_Device_–_system_";
CM_ SG_ 2314274302 Override "1_=_Yes,0_=_No.Yes_means_a_temporary_interruption_of_selected_Steer_mode.As_long_as_this_field_is_Yes,Steer_Mode_and_Turn_Mode_shall_be_ignored_by_heading/track_Ctrl_and_its_computing_parts_shall_operate_as_if_manual_Steer_was_selected.";
CM_ SG_ 2314274302 OffTrackLimitExceeded "MSB/LSB:__00_=_[No,_Off,_Disabled,_Reset,_'0'],_01_=_[Yes,_On,_Enabled,_Set,_'1'],_10_=_Error,_11=_[Unavailable,_Unknown]";
CM_ SG_ 2314274302 OffHeadingLimitExceeded "MSB/LSB:__00_=_[No,_Off,_Disabled,_Reset,_'0'],_01_=_[Yes,_On,_Enabled,_Set,_'1'],_10_=_Error,_11=_[Unavailable,_Unknown]";
CM_ SG_ 2314274302 RudderLimitExceeded "MSB/LSB:__00_=_[No,_Off,_Disabled,_Reset,_'0'],_01_=_[Yes,_On,_Enabled,_Set,_'1'],_10_=_Error,_11=_[Unavailable,_Unknown]";
CM_ BO_ 2583299582 "This_PGN_provides_a_single_Trans_that_contains_relevant_almanac_data_for_GPS_productsalmanac_contains_satellite_vehicle_coursebital_parametersThis_information_is_not_considered_precise_and_is_only_valid_for_several_months_at_a_timeGPS_products_receive_";
CM_ SG_ 2583299582 ClockParameter2 "Clock_Parameter_2.__Reference_ICD-GPS-200_Table_20-VI_for_scaling_factors_and_units.";
CM_ SG_ 2583299582 ClockParameter1 "Clock_Parameter_1.__Reference_ICD-GPS-200_Table_20-VI_for_scaling_factors_and_units.";
CM_ SG_ 2583299582 MeanAnomaly "Mean_anomaly.__Reference_ICD-GPS-200_Table_20-VI_for_scaling_factors_and_units.";
CM_ SG_ 2583299582 LongitudeOfAscensionNode "Longitude_of_ascension_node.__Reference_ICD-GPS-200_Table_20-VI_for_scaling_factors_and_units.";
CM_ SG_ 2583299582 ArgumentOfPerigee "Argument_of_Perigee.__Reference_ICD-GPS-200_Table_20-VI_for_scaling_factors_and_units.";
CM_ SG_ 2583299582 RootOfSemimajorAxis "Root_of_semi-major_axis.__Reference_ICD-GPS-200_Table_20-VI_for_scaling_factors_and_units.";
CM_ SG_ 2583299582 RateOfRightAscension "Rate_of_right_ascension,_OMEGADOT.__Reference_ICD-GPS-200_Table_20-VI_for_scaling_factors_and_units.";
CM_ SG_ 2583299582 InclinationAngle "Inclination_angle.__Reference_ICD-GPS-200_Table_20-VI_for_scaling_factors_and_units.";
CM_ SG_ 2583299582 AlmanacReferenceTime "Almanac_reference_time.__Reference_ICD-GPS-200_Table_20-VI_for_scaling_factors_and_units.";
CM_ SG_ 2583299582 Eccentricity "Eccentricity,_e.__Reference_ICD-GPS-200_Table_20-VI_for_scaling_factors_and_units.";
CM_ SG_ 2583299582 SVHealthBits "SV_health,_bits_17-24_of_each_almanac_page.__Reference_ICD-GPS-200_paragraph_20.3.3.5.1.3,_Table_20-VII_and_Table_20-VIII";
CM_ SG_ 2583299582 GPSWeekNumber "GPS_week_number._Starting_on_6_Jan.,_1980.__The_GPS_week_number_roll_over_will_not_affect_this_value,_i.e.,_it_will_continue_to_count_up_1022,_1023,_1024,_1025.";
CM_ SG_ 2583299582 PRN "0_=_value_not_used,_1-32_=_GPS,_33-64_=_SBAS,Satellite,Based_Augmentation_System(ie_WAAS)_65-96_=_GLONASS._For_GLONASS,satellites_are_identified_by_64+satellite_slot_number.slot_numbers_are_1_through_24_for_full_GLONASS_constellation_of_24_satellite";
CM_ BO_ 2583299326 "GNSS_information_on_current_satellites_in_view_tagged_by_sequence_IDInformation_includes_PRN,elevation,azimuth,and_SNRField_4_defines_number_of_satellitesFields_5_thru_11_define_satellite_number_and_informationThese_fields_sequentially_repeated_for_ea";
CM_ SG_ 2583299326 PRNStatusN "0___=_Not_Tracked,_1_=_Tracked_but_not_used_in_solution,_2_=_Used_in_solution_without_Diff_corrections,_3_=_Diff_Corrections_available,_4_=_Tracked_with_Diff_Corrections,_5_=_used_with_Diff_Corrections,_6-13_=Reserved,_14_=_E";
CM_ SG_ 2583299326 AzimuthN "Degrees_clockwise_relative_to_True_North.";
CM_ SG_ 2583299326 ElevationN "Angle_above_or_below_the_horizon._-90°_to_+90°_negative_below_the_horizon";
CM_ SG_ 2583299326 PRNN "0_=_value_not_used,_1-32_=_GPS,_33-64_=_SBAS,Satellite,Based_Augmentation_System(ie_WAAS)_65-96_=_GLONASS._For_GLONASS,satellites_are_identified_by_64+satellite_slot_number.slot_numbers_are_1_through_24_for_full_GLONASS_constellation_of_24_satellite";
CM_ SG_ 2583299326 PRNStatus1 "0___=_Not_Tracked,_1_=_Tracked_but_not_used_in_solution,_2_=_Used_in_solution_without_Diff_corrections,_3_=_Diff_Corrections_available,_4_=_Tracked_with_Diff_Corrections,_5_=_used_with_Diff_Corrections,_6-13_=Reserved,_14_=_E";
CM_ SG_ 2583299326 Azimuth1 "Degrees_clockwise_relative_to_True_North.";
CM_ SG_ 2583299326 Elevation1 "Angle_above_or_below_the_horizon._-90°_to_+90°_negative_below_the_horizon";
CM_ SG_ 2583299326 PRN1 "0_=_value_not_used,_1-32_=_GPS,_33-64_=_SBAS,Satellite,Based_Augmentation_System(ie_WAAS)_65-96_=_GLONASS._For_GLONASS,satellites_are_identified_by_64+satellite_slot_number.slot_numbers_are_1_through_24_for_full_GLONASS_constellation_of_24_satellite";
CM_ SG_ 2583299326 NumberOfSVs_ "Numeric_count,_event_counter,_sequence_counter";
CM_ SG_ 2583299326 SID "An_upward_counting_number_used_to_tie_related_information_together_between_different_PGNs.For_example,SID_would_be_used_to_tie_together_COG,SOG_and_RAIM_values_to_a_given_Pos.255=no_valid_Pos_fix_to_tie_it_to.Range_0_to_250_for_valid_Pos_fixes.";
CM_ BO_ 2583300862 "This_PGN_is_used_to_report_the_control_parameters_for_a_GNSS_Receiver_Autonomous_Integrity_Monitoring_RAIM_process__The_Command_Group_Function_PGN_126208_provides_the_means_to_set_these_values_over_the_network";
CM_ SG_ 2583300862 RadialPosErrorMaxThreshold "Error_distances_expressed_in_meters.";
CM_ BO_ 2583238398 "Bearing_and_distance_from_the_origin_mark_to_the_destination_mark,_calculated_at_the_origin_mark,_for_any_two_arbitrary_generic_marks_The_calculation_type_Rhumb_Line,_Great_Circle_is_specified,_as_well_as_the_bearing_reference_Mag,_True";
CM_ SG_ 2583238398 DestinationMarkID "Number_of_route,_waypoint,_event,_mark,_etc.";
CM_ SG_ 2583238398 OriginMarkId "Number_of_route,_waypoint,_event,_mark,_etc.";
CM_ SG_ 2583238398 DestinationMarkType "0___=_Collision,__1_=_Turning_Point,_2_=_Reference_(general),_3_=_Wheelover,_4_=_Waypoint,_5-13_=_Reserved,_14_=_Error,_15_=_Null";
CM_ SG_ 2583238398 OriginMarkType "0___=_Collision,__1_=_Turning_Point,_2_=_Reference_(general),_3_=_Wheelover,_4_=_Waypoint,_5-13_=_Reserved,_14_=_Error,_15_=_Null";
CM_ SG_ 2583238398 BearingiginToDestination "The_horizontal_direction_of_one_terrestrial_point_from_another,_expressed_as_the_angular_distance_from_a_reference_direction,_measured_from_000_at_the_reference_direction_clockwise_through_359_degrees.";
CM_ SG_ 2583238398 CalculationType "0_=_Great_Circle_calculations,__1_=_Rhumb_Line_calculations,_2_=_Error,_3_=_Null";
CM_ SG_ 2583238398 BearingRef "0_=_True,__1_=_Magnetic,_2_=_Error,_3_=_Null";
CM_ SG_ 2583238398 SID "An_upward_counting_number_used_to_tie_related_information_together_between_different_PGNs.For_example,SID_would_be_used_to_tie_together_COG,SOG_and_RAIM_values_to_a_given_Pos.255=no_valid_Pos_fix_to_tie_it_to.Range_0_to_250_for_valid_Pos_fixes.";
CM_ BO_ 2381450750 "Universal_status_report_for_multiple_banks_of_two-state_indicators";
CM_ SG_ 2381450750 Indic28 "MSB/LSB:__00_=_[No,_Off,_Disabled,_Reset,_'0'],_01_=_[Yes,_On,_Enabled,_Set,_'1'],_10_=_Error,_11=_[Unavailable,_Unknown]";
CM_ SG_ 2381450750 Indic27 "MSB/LSB:__00_=_[No,_Off,_Disabled,_Reset,_'0'],_01_=_[Yes,_On,_Enabled,_Set,_'1'],_10_=_Error,_11=_[Unavailable,_Unknown]";
CM_ SG_ 2381450750 Indic26 "MSB/LSB:__00_=_[No,_Off,_Disabled,_Reset,_'0'],_01_=_[Yes,_On,_Enabled,_Set,_'1'],_10_=_Error,_11=_[Unavailable,_Unknown]";
CM_ SG_ 2381450750 Indic25 "MSB/LSB:__00_=_[No,_Off,_Disabled,_Reset,_'0'],_01_=_[Yes,_On,_Enabled,_Set,_'1'],_10_=_Error,_11=_[Unavailable,_Unknown]";
CM_ SG_ 2381450750 Indic24 "MSB/LSB:__00_=_[No,_Off,_Disabled,_Reset,_'0'],_01_=_[Yes,_On,_Enabled,_Set,_'1'],_10_=_Error,_11=_[Unavailable,_Unknown]";
CM_ SG_ 2381450750 Indic23 "MSB/LSB:__00_=_[No,_Off,_Disabled,_Reset,_'0'],_01_=_[Yes,_On,_Enabled,_Set,_'1'],_10_=_Error,_11=_[Unavailable,_Unknown]";
CM_ SG_ 2381450750 Indic22 "MSB/LSB:__00_=_[No,_Off,_Disabled,_Reset,_'0'],_01_=_[Yes,_On,_Enabled,_Set,_'1'],_10_=_Error,_11=_[Unavailable,_Unknown]";
CM_ SG_ 2381450750 Indic21 "MSB/LSB:__00_=_[No,_Off,_Disabled,_Reset,_'0'],_01_=_[Yes,_On,_Enabled,_Set,_'1'],_10_=_Error,_11=_[Unavailable,_Unknown]";
CM_ SG_ 2381450750 Indic20 "MSB/LSB:__00_=_[No,_Off,_Disabled,_Reset,_'0'],_01_=_[Yes,_On,_Enabled,_Set,_'1'],_10_=_Error,_11=_[Unavailable,_Unknown]";
CM_ SG_ 2381450750 Indic19 "MSB/LSB:__00_=_[No,_Off,_Disabled,_Reset,_'0'],_01_=_[Yes,_On,_Enabled,_Set,_'1'],_10_=_Error,_11=_[Unavailable,_Unknown]";
CM_ SG_ 2381450750 Indic18 "MSB/LSB:__00_=_[No,_Off,_Disabled,_Reset,_'0'],_01_=_[Yes,_On,_Enabled,_Set,_'1'],_10_=_Error,_11=_[Unavailable,_Unknown]";
CM_ SG_ 2381450750 Indic17 "MSB/LSB:__00_=_[No,_Off,_Disabled,_Reset,_'0'],_01_=_[Yes,_On,_Enabled,_Set,_'1'],_10_=_Error,_11=_[Unavailable,_Unknown]";
CM_ SG_ 2381450750 Indic16 "MSB/LSB:__00_=_[No,_Off,_Disabled,_Reset,_'0'],_01_=_[Yes,_On,_Enabled,_Set,_'1'],_10_=_Error,_11=_[Unavailable,_Unknown]";
CM_ SG_ 2381450750 Indic15 "MSB/LSB:__00_=_[No,_Off,_Disabled,_Reset,_'0'],_01_=_[Yes,_On,_Enabled,_Set,_'1'],_10_=_Error,_11=_[Unavailable,_Unknown]";
CM_ SG_ 2381450750 Indic14 "MSB/LSB:__00_=_[No,_Off,_Disabled,_Reset,_'0'],_01_=_[Yes,_On,_Enabled,_Set,_'1'],_10_=_Error,_11=_[Unavailable,_Unknown]";
CM_ SG_ 2381450750 Indic13 "MSB/LSB:__00_=_[No,_Off,_Disabled,_Reset,_'0'],_01_=_[Yes,_On,_Enabled,_Set,_'1'],_10_=_Error,_11=_[Unavailable,_Unknown]";
CM_ SG_ 2381450750 Indic12 "MSB/LSB:__00_=_[No,_Off,_Disabled,_Reset,_'0'],_01_=_[Yes,_On,_Enabled,_Set,_'1'],_10_=_Error,_11=_[Unavailable,_Unknown]";
CM_ SG_ 2381450750 Indic11 "MSB/LSB:__00_=_[No,_Off,_Disabled,_Reset,_'0'],_01_=_[Yes,_On,_Enabled,_Set,_'1'],_10_=_Error,_11=_[Unavailable,_Unknown]";
CM_ SG_ 2381450750 Indic10 "MSB/LSB:__00_=_[No,_Off,_Disabled,_Reset,_'0'],_01_=_[Yes,_On,_Enabled,_Set,_'1'],_10_=_Error,_11=_[Unavailable,_Unknown]";
CM_ SG_ 2381450750 Indic9 "MSB/LSB:__00_=_[No,_Off,_Disabled,_Reset,_'0'],_01_=_[Yes,_On,_Enabled,_Set,_'1'],_10_=_Error,_11=_[Unavailable,_Unknown]";
CM_ SG_ 2381450750 Indic8 "MSB/LSB:__00_=_[No,_Off,_Disabled,_Reset,_'0'],_01_=_[Yes,_On,_Enabled,_Set,_'1'],_10_=_Error,_11=_[Unavailable,_Unknown]";
CM_ SG_ 2381450750 Indic7 "MSB/LSB:__00_=_[No,_Off,_Disabled,_Reset,_'0'],_01_=_[Yes,_On,_Enabled,_Set,_'1'],_10_=_Error,_11=_[Unavailable,_Unknown]";
CM_ SG_ 2381450750 Indic6 "MSB/LSB:__00_=_[No,_Off,_Disabled,_Reset,_'0'],_01_=_[Yes,_On,_Enabled,_Set,_'1'],_10_=_Error,_11=_[Unavailable,_Unknown]";
CM_ SG_ 2381450750 Indic5 "MSB/LSB:__00_=_[No,_Off,_Disabled,_Reset,_'0'],_01_=_[Yes,_On,_Enabled,_Set,_'1'],_10_=_Error,_11=_[Unavailable,_Unknown]";
CM_ SG_ 2381450750 Indic4 "MSB/LSB:__00_=_[No,_Off,_Disabled,_Reset,_'0'],_01_=_[Yes,_On,_Enabled,_Set,_'1'],_10_=_Error,_11=_[Unavailable,_Unknown]";
CM_ SG_ 2381450750 Indic3 "MSB/LSB:__00_=_[No,_Off,_Disabled,_Reset,_'0'],_01_=_[Yes,_On,_Enabled,_Set,_'1'],_10_=_Error,_11=_[Unavailable,_Unknown]";
CM_ SG_ 2381450750 Indic2 "MSB/LSB:__00_=_[No,_Off,_Disabled,_Reset,_'0'],_01_=_[Yes,_On,_Enabled,_Set,_'1'],_10_=_Error,_11=_[Unavailable,_Unknown]";
CM_ SG_ 2381450750 Indic1 "MSB/LSB:__00_=_[No,_Off,_Disabled,_Reset,_'0'],_01_=_[Yes,_On,_Enabled,_Set,_'1'],_10_=_Error,_11=_[Unavailable,_Unknown]";
CM_ SG_ 2381450750 IndicatorBankInstance "Number_of_route,_waypoint,_event,_mark,_etc.";
CM_ BO_ 2582779134 "Provides_parametric_data_for_a_specific_battery,_indicated_by_the_battery_instance_field_Used_primarily_by_display_or_instrumentation_devices,_but_may_also_be_used_by_battery_management_controls";
CM_ SG_ 2582779134 SID "An_upward_counting_number_used_to_tie_related_information_together_between_different_PGNs.For_example,SID_would_be_used_to_tie_together_COG,SOG_and_RAIM_values_to_a_given_Pos.255=no_valid_Pos_fix_to_tie_it_to.Range_0_to_250_for_valid_Pos_fixes.";
CM_ SG_ 2582779134 BatteryCurrent "+_=_current_consumed,_-_=_current_supplied";
CM_ SG_ 2582779134 BatteryInstance "Number_of_route,_waypoint,_event,_mark,_etc.";
CM_ BO_ 2381388286 "This_PGN_provides_a_single_Trans_that_describes_Pos_of_a_vessel_relative_to_both_horizontal_and_vertical_planesThis_would_typically_be_used_for_vessel_stabilization,vessel_Ctrl_and_onboard_platform_stabilization_Products_that_directly_interface_to_pi";
CM_ SG_ 2381388286 Roll "Oscillation_of_ship_about_it's_longitudinal_axis.__Roll_to_the_starboard_is_positive.";
CM_ SG_ 2381388286 Pitch_ "Oscillation_of_ship_about_it's_latitudinal_axis.__Bow_moving_up_is_positive.";
CM_ SG_ 2381388286 Yaw "Oscillation_of_ship_about_it's_vertical_axis.__Bow_moving_to_starboard_is_positive.";
CM_ SG_ 2381388286 SID "An_upward_counting_number_used_to_tie_related_information_together_between_different_PGNs.For_example,SID_would_be_used_to_tie_together_COG,SOG_and_RAIM_values_to_a_given_Pos.255=no_valid_Pos_fix_to_tie_it_to.Range_0_to_250_for_valid_Pos_fixes.";
CM_ BO_ 2314732798 "TheAltitude_Delta,High_Precision_Rapid_UpdateParameter_Group_is_intended_for_Apps_where_very_high_precision_and_very_fast_update_rates_are_needed_for_altitude_and_course_over_ground_dataThis_PG_can_provide_delta_altitude_changes_down_to_1_millimeter,a_";
CM_ SG_ 2314732798 CourseOverGround "The_direction_of_the_path_over_ground_actually_followed_by_a_vessel.";
CM_ SG_ 2314732798 Direction "0_=_True,__1_=_Magnetic,_2_=_Error,_3_=_Null";
CM_ SG_ 2314732798 GNSSQuality "0_=_no_GPS,_1_=_GNSS_fix,_2_=_DGNSS_fix,_3_=_Precise_GNSS*,_4_=_RTK_Fixed_Integer,_5_=_RTK_Float,_6_=_Est(DR)mode,_7_=_Manual_Input,_8_=_Simulate_mode,_9-13_=_Reserved,_14_=_Error,_15_=_Null.*Precise_GNSS_means_no_deliberate_degradation(such_as";
CM_ SG_ 2314732798 SequenceID_ "An_upward_counting_number_used_to_tie_related_information_together_between_different_PGNs.For_example,SID_would_be_used_to_tie_together_COG,SOG_and_RAIM_values_to_a_given_Pos.255=no_valid_Pos_fix_to_tie_it_to.Range_0_to_250_for_valid_Pos_fixes.";
CM_ BO_ 2650474750 "This_parameter_group_provides_data_associated_with_ITU-R_M1371_Msg_10_UTC_and_Date_Inquiry_Msg_used_to_Rq_current_UTC_and_dateAn_AIS_device_may_generate_this_parameter_group_either_upon_receiving_a_VHF_data_link_Msg_10,or_upon_receipt_of_an_ISO_NMEA_Rq_";
CM_ SG_ 2650474750 DestinationID "Number_of_route,_waypoint,_event,_mark,_etc.";
CM_ SG_ 2650474750 AISTransceiverInformation "0_=_Channel_A_VDL_reception,_1_=_Channel_B_VDL_reception,_2_=_Channel_A_VDL_transmission,_3_=_Channel_B_VDL_transmission,_4_=_Own_information_not_broadcast,_5-31_=_Reserved.";
CM_ SG_ 2650474750 SourceID "Number_of_route,_waypoint,_event,_mark,_etc.";
CM_ SG_ 2650474750 RepeatIndicator "Used_by_the_repeater_to_indicate_how_many_times_a_message_has_been_repeated_(range_of_0_to_3)._0_=_Default_1_=_First_retransmission_2_=_Second_retransmission_3_=_Final_retransmission_See_ITU-R_M.1371-1_for_more_information.";
CM_ SG_ 2650474750 MsgID "Message_Identifier_(range_of_0_to_63)._See_ITU-R_M.1371-1_for_more_information.";
CM_ BO_ 2650472958 "This_parameter_group_provides_data_from_ITU-R_M1371_Msg_4_Base_Station_Report_providing_Pos,time,date,and_current_slot_number_of_a_base_station,and_11_UTC_and_date_Resp_Msg_providing_current_UTC_and_date_if_availableAn_AIS_device_may_generate_this_param";
CM_ SG_ 2650472958 TypeOfElectronicPosingDevice "0=Undefined_(default),__1=GPS,_2=GLONASS,_3=Combined_GPS/GLONASS,_4=Loran-C,_5=Chayka,_6=Integrated_Navigation_System,_7=Surveyed_(Base_Station),_8-15=Reserve_for_future_use._See_ITU-R_M.1371-1_for_more_information.";
CM_ SG_ 2650472958 PosDate "Days_since_January_1,_1970,___Date_is_relative_to_UTC_Time.";
CM_ SG_ 2650472958 AISTransceiverInformation "0_=_Channel_A_VDL_reception,_1_=_Channel_B_VDL_reception,_2_=_Channel_A_VDL_transmission,_3_=_Channel_B_VDL_transmission,_4_=_Own_information_not_broadcast,_5-31_=_Reserved.";
CM_ SG_ 2650472958 CommunicationState "The_Communication_State_contains_information_used_by_the_various_TDMA_slot_allocation_algorithms_and_synchronization_information_See_ITU-R_M.1371-1_for_more_information.";
CM_ SG_ 2650472958 PosTime "24_hour_clock,_0_=__midnight,__time_is_in_UTC";
CM_ SG_ 2650472958 RAIMflag "0_=_RAIM_not_in_use_(default),_1_=_RAIM_in_use_See_ITU-R_M.1371-1_for_more_information.";
CM_ SG_ 2650472958 PosAccuracy "0=low_accuracy>10m_such_as_nondifferential_GNSS_(default),__1=high_accuracy_<10m_such_as_DGNSS_See_ITU-R_M.1371-1_for_more_information.";
CM_ SG_ 2650472958 UserID "Number_of_route,_waypoint,_event,_mark,_etc.";
CM_ SG_ 2650472958 RepeatIndicator "Used_by_the_repeater_to_indicate_how_many_times_a_message_has_been_repeated_(range_of_0_to_3)._0_=_Default_1_=_First_retransmission_2_=_Second_retransmission_3_=_Final_retransmission_See_ITU-R_M.1371-1_for_more_information.";
CM_ SG_ 2650472958 MsgID "Message_Identifier_(range_of_0_to_63)._See_ITU-R_M.1371-1_for_more_information.";
CM_ BO_ 2650475262 "This_parameter_group_provides_data_associated_with_ITU-R_M1371_Msg_14_Safety_Related_Broadcast_Msg_supporting_broadcast_communication_of_safety_related_dataAn_AIS_device_may_generate_this_parameter_group_either_upon_receiving_a_VHF_data_link_Msg_14,or_u";
CM_ SG_ 2650475262 SafetyRelatedText "Name_of_place,_route,_waypoint,_destination,_vessel,_vehicle,_etc.";
CM_ SG_ 2650475262 AISTransceiverInformation "0_=_Channel_A_VDL_reception,_1_=_Channel_B_VDL_reception,_2_=_Channel_A_VDL_transmission,_3_=_Channel_B_VDL_transmission,_4_=_Own_information_not_broadcast,_5-31_=_Reserved.";
CM_ SG_ 2650475262 SourceID "Number_of_route,_waypoint,_event,_mark,_etc.";
CM_ SG_ 2650475262 RepeatIndicator "Used_by_the_repeater_to_indicate_how_many_times_a_message_has_been_repeated_(range_of_0_to_3)._0_=_Default_1_=_First_retransmission_2_=_Second_retransmission_3_=_Final_retransmission_See_ITU-R_M.1371-1_for_more_information.";
CM_ SG_ 2650475262 MsgID "Message_Identifier_(range_of_0_to_63)._See_ITU-R_M.1371-1_for_more_information.";
CM_ BO_ 2650474238 "This_parameter_group_provides_data_associated_with_ITU-R_M1371_Msg_9_SAR_Aircraft_Pos_Report_Msg_for_Airborne_AIS_units_conducting_Search_and_Rescue_operationsAn_AIS_device_may_generate_this_parameter_group_either_upon_receiving_a_VHF_data_link_Msg_9,or";
CM_ SG_ 2650474238 DataTerminalEquipment "0=Available,_1=not_available._See_ITU-R_M.1371-1_for_more_information.";
CM_ SG_ 2650474238 AISTransceiverInformation "0_=_Channel_A_VDL_reception,_1_=_Channel_B_VDL_reception,_2_=_Channel_A_VDL_transmission,_3_=_Channel_B_VDL_transmission,_4_=_Own_information_not_broadcast,_5-31_=_Reserved.";
CM_ SG_ 2650474238 CommunicationState "The_Communication_State_contains_information_used_by_the_various_TDMA_slot_allocation_algorithms_and_synchronization_information_See_ITU-R_M.1371-1_for_more_information.";
CM_ SG_ 2650474238 COG "The_direction_of_the_path_over_ground_actually_followed_by_a_vessel.";
CM_ SG_ 2650474238 TimeStamp "0-59=UTC_second_when_report_was_generated,_60=time_stamp_not_available(default),_61=Posing_system_is_in_manual_input_mode,_62=Electronic_Pos_fixing_system_operates_in_Est(dead_reckoning)mode,_63=Posing_system_is_inoperative_See_ITU-R_M.1371-1_for_m";
CM_ SG_ 2650474238 RAIMFlag "0_=_RAIM_not_in_use_(default),_1_=_RAIM_in_use_See_ITU-R_M.1371-1_for_more_information.";
CM_ SG_ 2650474238 PosAccuracy "0=low_accuracy>10m_such_as_nondifferential_GNSS_(default),__1=high_accuracy_<10m_such_as_DGNSS_See_ITU-R_M.1371-1_for_more_information.";
CM_ SG_ 2650474238 UserID "Number_of_route,_waypoint,_event,_mark,_etc.";
CM_ SG_ 2650474238 RepeatIndicator "Used_by_the_repeater_to_indicate_how_many_times_a_message_has_been_repeated_(range_of_0_to_3)._0_=_Default_1_=_First_retransmission_2_=_Second_retransmission_3_=_Final_retransmission_See_ITU-R_M.1371-1_for_more_information.";
CM_ SG_ 2650474238 MsgID "Message_Identifier_(range_of_0_to_63)._See_ITU-R_M.1371-1_for_more_information.";
CM_ BO_ 2650475518 "This_parameter_group_provides_data_associated_with_ITU-R_M1371_Msg_15_Interrogation_Msg_used_to_Rq_a_specific_ITU-R_M1371_Msg_resulting_in_Resps_from_one_more_AIS_mobile_unitsAn_AIS_device_may_generate_this_parameter_group_either_upon_receiving_a_VHF_d";
CM_ SG_ 2650475518 SlotOffset21 "Number_of_route,_waypoint,_event,_mark,_etc.";
CM_ SG_ 2650475518 MsgID21 "Message_Identifier_(range_of_0_to_63)._See_ITU-R_M.1371-1_for_more_information.";
CM_ SG_ 2650475518 DestinationID2 "Number_of_route,_waypoint,_event,_mark,_etc.";
CM_ SG_ 2650475518 SlotOffset12 "Number_of_route,_waypoint,_event,_mark,_etc.";
CM_ SG_ 2650475518 MsgID12 "Message_Identifier_(range_of_0_to_63)._See_ITU-R_M.1371-1_for_more_information.";
CM_ SG_ 2650475518 SlotOffset11 "Number_of_route,_waypoint,_event,_mark,_etc.";
CM_ SG_ 2650475518 MsgID11 "Message_Identifier_(range_of_0_to_63)._See_ITU-R_M.1371-1_for_more_information.";
CM_ SG_ 2650475518 DestinationID1 "Number_of_route,_waypoint,_event,_mark,_etc.";
CM_ SG_ 2650475518 AISTransceiverInformation "0_=_Channel_A_VDL_reception,_1_=_Channel_B_VDL_reception,_2_=_Channel_A_VDL_transmission,_3_=_Channel_B_VDL_transmission,_4_=_Own_information_not_broadcast,_5-31_=_Reserved.";
CM_ SG_ 2650475518 SourceID "Number_of_route,_waypoint,_event,_mark,_etc.";
CM_ SG_ 2650475518 RepeatIndicator "Used_by_the_repeater_to_indicate_how_many_times_a_message_has_been_repeated_(range_of_0_to_3)._0_=_Default_1_=_First_retransmission_2_=_Second_retransmission_3_=_Final_retransmission_See_ITU-R_M.1371-1_for_more_information.";
CM_ SG_ 2650475518 MsgID "Message_Identifier_(range_of_0_to_63)._See_ITU-R_M.1371-1_for_more_information.";
CM_ BO_ 2650476030 "This_parameter_group_provides_data_associated_with_ITU-R_M1371_Msg_20_Data_Link_Management_Msg_for_reserving_slots_for_base_stationsAn_AIS_device_may_generate_this_parameter_group_either_upon_receiving_a_VHF_data_link_Msg_20,or_upon_receipt_of_an_ISO_NM";
CM_ SG_ 2650476030 Increment4 "Number_of_route,_waypoint,_event,_mark,_etc.";
CM_ SG_ 2650476030 TimeOut4 "Number_of_route,_waypoint,_event,_mark,_etc.";
CM_ SG_ 2650476030 NumberOfSlots4 "Number_of_route,_waypoint,_event,_mark,_etc.";
CM_ SG_ 2650476030 OffsetNumber4 "Number_of_route,_waypoint,_event,_mark,_etc.";
CM_ SG_ 2650476030 Increment3 "Number_of_route,_waypoint,_event,_mark,_etc.";
CM_ SG_ 2650476030 TimeOut3 "Number_of_route,_waypoint,_event,_mark,_etc.";
CM_ SG_ 2650476030 NumberOfSlots3 "Number_of_route,_waypoint,_event,_mark,_etc.";
CM_ SG_ 2650476030 OffsetNumber3 "Number_of_route,_waypoint,_event,_mark,_etc.";
CM_ SG_ 2650476030 Increment2 "Number_of_route,_waypoint,_event,_mark,_etc.";
CM_ SG_ 2650476030 TimeOut2 "Number_of_route,_waypoint,_event,_mark,_etc.";
CM_ SG_ 2650476030 NumberOfSlots2 "Number_of_route,_waypoint,_event,_mark,_etc.";
CM_ SG_ 2650476030 OffsetNumber2 "Number_of_route,_waypoint,_event,_mark,_etc.";
CM_ SG_ 2650476030 Increment1 "Number_of_route,_waypoint,_event,_mark,_etc.";
CM_ SG_ 2650476030 TimeOut1 "Number_of_route,_waypoint,_event,_mark,_etc.";
CM_ SG_ 2650476030 NumberOfSlots1 "Number_of_route,_waypoint,_event,_mark,_etc.";
CM_ SG_ 2650476030 OffsetNumber1 "Number_of_route,_waypoint,_event,_mark,_etc.";
CM_ SG_ 2650476030 AISTransceiverInformation "0_=_Channel_A_VDL_reception,_1_=_Channel_B_VDL_reception,_2_=_Channel_A_VDL_transmission,_3_=_Channel_B_VDL_transmission,_4_=_Own_information_not_broadcast,_5-31_=_Reserved.";
CM_ SG_ 2650476030 SourceStationID "Number_of_route,_waypoint,_event,_mark,_etc.";
CM_ SG_ 2650476030 RepeatIndicator "Used_by_the_repeater_to_indicate_how_many_times_a_message_has_been_repeated_(range_of_0_to_3)._0_=_Default_1_=_First_retransmission_2_=_Second_retransmission_3_=_Final_retransmission_See_ITU-R_M.1371-1_for_more_information.";
CM_ SG_ 2650476030 MsgID "Message_Identifier_(range_of_0_to_63)._See_ITU-R_M.1371-1_for_more_information.";
CM_ BO_ 2583363838 "This_parameter_group_provides_data_associated_with_ITU-R_M1371_Msg_17_GNSS_Broadcast_Binary_Msg_containing_DGNSS_corrections_from_a_base_stationAn_AIS_device_may_generate_this_parameter_group_either_upon_receiving_a_VHF_data_link_Msg_17,or_upon_receipt_";
CM_ SG_ 2583363838 NumberOfBitsInBinaryDataField "Number_of_route,_waypoint,_event,_mark,_etc.";
CM_ SG_ 2583363838 AISTransceiverInformation "0_=_Channel_A_VDL_reception,_1_=_Channel_B_VDL_reception,_2_=_Channel_A_VDL_transmission,_3_=_Channel_B_VDL_transmission,_4_=_Own_information_not_broadcast,_5-31_=_Reserved.";
CM_ SG_ 2583363838 SourceID "Number_of_route,_waypoint,_event,_mark,_etc.";
CM_ SG_ 2583363838 RepeatIndicator "Used_by_the_repeater_to_indicate_how_many_times_a_message_has_been_repeated_(range_of_0_to_3)._0_=_Default_1_=_First_retransmission_2_=_Second_retransmission_3_=_Final_retransmission_See_ITU-R_M.1371-1_for_more_information.";
CM_ SG_ 2583363838 MsgID "Message_Identifier_(range_of_0_to_63)._See_ITU-R_M.1371-1_for_more_information.";
CM_ BO_ 2650473214 "This_parameter_group_provides_data_associated_with_ITU-R_M1371_Msg_5_Ship_Static_and_Voyage_Related_Data_MsgAn_AIS_device_may_generate_this_parameter_group_either_upon_receiving_a_VHF_data_link_Msg_5,or_upon_receipt_of_an_ISO_NMEA_Rq_PGNCmd_Group_Funct";
CM_ SG_ 2650473214 Destination "Length_specified_by_PGN_field_definition.";
CM_ SG_ 2650473214 Name "Name_of_place,_route,_waypoint,_destination,_vessel,_vehicle,_etc.";
CM_ SG_ 2650473214 CallSign "Length_specified_by_PGN_field_definition.";
CM_ SG_ 2650473214 IMO "Number_of_route,_waypoint,_event,_mark,_etc.";
CM_ SG_ 2650473214 UserID "Number_of_route,_waypoint,_event,_mark,_etc.";
CM_ SG_ 2650473214 RepeatIndicator "Used_by_the_repeater_to_indicate_how_many_times_a_message_has_been_repeated_(range_of_0_to_3)._0_=_Default_1_=_First_retransmission_2_=_Second_retransmission_3_=_Final_retransmission_See_ITU-R_M.1371-1_for_more_information.";
CM_ SG_ 2650473214 MsgID "Message_Identifier_(range_of_0_to_63)._See_ITU-R_M.1371-1_for_more_information.";
CM_ BO_ 2448953342 "This_parameter_group_provides_data_associated_with_ITU-R_M1371_Msg_18_Standard_Class_B_Equipment_Pos_ReportAn_AIS_device_may_generate_this_parameter_group_either_upon_receiving_a_VHF_data_link_Msg_18,or_upon_receipt_of_an_ISO_NMEA_Rq_PGNsee_ITU-R_M137";
CM_ SG_ 2448953342 ComminicationStateSelectorFlag "0=SOTDMA_communication_state,_1=ITDMA_communication_state_follows._See_ITU-R_M.1371-1_for_more_information.";
CM_ SG_ 2448953342 TrueHeading "Degrees_clockwise_relative_to_True_North.";
CM_ SG_ 2448953342 AISTransceiverInformation "0_=_Channel_A_VDL_reception,_1_=_Channel_B_VDL_reception,_2_=_Channel_A_VDL_transmission,_3_=_Channel_B_VDL_transmission,_4_=_Own_information_not_broadcast,_5-31_=_Reserved.";
CM_ SG_ 2448953342 CommunicationState "The_Communication_State_contains_information_used_by_the_various_TDMA_slot_allocation_algorithms_and_synchronization_information_See_ITU-R_M.1371-1_for_more_information.";
CM_ SG_ 2448953342 COG "The_direction_of_the_path_over_ground_actually_followed_by_a_vessel.";
CM_ SG_ 2448953342 TimeStamp "0-59=UTC_second_when_report_was_generated,_60=time_stamp_not_available(default),_61=Posing_system_is_in_manual_input_mode,_62=Electronic_Pos_fixing_system_operates_in_Est(dead_reckoning)mode,_63=Posing_system_is_inoperative_See_ITU-R_M.1371-1_for_m";
CM_ SG_ 2448953342 RAIMflag "0_=_RAIM_not_in_use_(default),_1_=_RAIM_in_use_See_ITU-R_M.1371-1_for_more_information.";
CM_ SG_ 2448953342 PosAccuracy "0=low_accuracy>10m_such_as_nondifferential_GNSS_(default),__1=high_accuracy_<10m_such_as_DGNSS_See_ITU-R_M.1371-1_for_more_information.";
CM_ SG_ 2448953342 UserID "Number_of_route,_waypoint,_event,_mark,_etc.";
CM_ SG_ 2448953342 RepeatIndicator "Used_by_the_repeater_to_indicate_how_many_times_a_message_has_been_repeated_(range_of_0_to_3)._0_=_Default_1_=_First_retransmission_2_=_Second_retransmission_3_=_Final_retransmission_See_ITU-R_M.1371-1_for_more_information.";
CM_ SG_ 2448953342 MsgID "Message_Identifier_(range_of_0_to_63)._See_ITU-R_M.1371-1_for_more_information.";
CM_ BO_ 2448953598 "This_parameter_group_provides_data_associated_with_ITU-R_M1371_Msg_19_Ex_Class_B_Equipment_Pos_Report_containing_Pos_and_static_informationAn_AIS_device_may_generate_this_parameter_group_either_upon_receiving_a_VHF_data_link_Msg_19,or_upon_receipt_of_an";
CM_ SG_ 2448953598 Name "Name_of_place,_route,_waypoint,_destination,_vessel,_vehicle,_etc.";
CM_ SG_ 2448953598 PosReferencePointAftOfShipsBow "Dependent_upon_PG_Field_definition.";
CM_ SG_ 2448953598 PosReferencePointFromStarboard "Dependent_upon_PG_Field_definition.";
CM_ SG_ 2448953598 ShipBeam "Dependent_upon_PG_Field_definition.";
CM_ SG_ 2448953598 ShipLength "Dependent_upon_PG_Field_definition.";
CM_ SG_ 2448953598 TypeOfElectronicPosingDevice "0=Undefined_(default),__1=GPS,_2=GLONASS,_3=Combined_GPS/GLONASS,_4=Loran-C,_5=Chayka,_6=Integrated_Navigation_System,_7=Surveyed_(Base_Station),_8-15=Reserve_for_future_use._See_ITU-R_M.1371-1_for_more_information.";
CM_ SG_ 2448953598 TrueHeading "Degrees_clockwise_relative_to_True_North.";
CM_ SG_ 2448953598 Ship_CargoType "0=Not_Available_or_no_ship_(default),__1-99=_(See_ITU-R_M.1371-1_Section_3.3.8.2.3.2_Table_18),_100-199=Reserved_for_Regional_(See_ITU-R_M.1371-1),_200-255=Reserved_for_future_(See_ITU-R_M.1371-1).";
CM_ SG_ 2448953598 COG "The_direction_of_the_path_over_ground_actually_followed_by_a_vessel.";
CM_ SG_ 2448953598 TimeStamp "0-59=UTC_second_when_report_was_generated,_60=time_stamp_not_available(default),_61=Posing_system_is_in_manual_input_mode,_62=Electronic_Pos_fixing_system_operates_in_Est(dead_reckoning)mode,_63=Posing_system_is_inoperative_See_ITU-R_M.1371-1_for_m";
CM_ SG_ 2448953598 RAIMflag "0_=_RAIM_not_in_use_(default),_1_=_RAIM_in_use_See_ITU-R_M.1371-1_for_more_information.";
CM_ SG_ 2448953598 PosAccuracy "0=low_accuracy>10m_such_as_nondifferential_GNSS_(default),__1=high_accuracy_<10m_such_as_DGNSS_See_ITU-R_M.1371-1_for_more_information.";
CM_ SG_ 2448953598 UserID "Number_of_route,_waypoint,_event,_mark,_etc.";
CM_ SG_ 2448953598 RepeatIndicator "Used_by_the_repeater_to_indicate_how_many_times_a_message_has_been_repeated_(range_of_0_to_3)._0_=_Default_1_=_First_retransmission_2_=_Second_retransmission_3_=_Final_retransmission_See_ITU-R_M.1371-1_for_more_information.";
CM_ SG_ 2448953598 MsgID "Message_Identifier_(range_of_0_to_63)._See_ITU-R_M.1371-1_for_more_information.";
CM_ BO_ 2566838526 "Commanded_Address";
CM_ SG_ 2566838526 AddressAssignment "The_source_address_that_is_to_be_assigned_to_the_CA_that_has_the_NAME_corresponding_to_the_one_conveyed_in_the_first_eight_bytes_of_this_Commanded_Address_message.";
CM_ SG_ 2566838526 IndustryGroup "0_=_Global_";
CM_ SG_ 2566838526 ManufacturerCode "Assigned_by_NMEA_2000_Committee";
BA_DEF_  "ProtocolType" STRING ;
BA_DEF_ SG_  "SystemSignalLongSymbol" STRING ;
BA_DEF_ BO_  "SystemMessageLongSymbol" STRING ;
BA_DEF_DEF_  "ProtocolType" "";
BA_DEF_DEF_  "SystemSignalLongSymbol" "";
BA_DEF_DEF_  "SystemMessageLongSymbol" "";
BA_ "ProtocolType" "NMEA2000";
VAL_ 2381842942 Time 0 "midnight,__time_is_in_UTC" ;
VAL_ 2381911550 MarkType 15 "Null" 14 "Error" 5 "Reserved" 4 "Waypoint" 3 "Wheelover" 2 "Reference_general" 1 "Turning_Point" 0 "Collision" ;
VAL_ 2381911550 SID 255 "nVldPsFxTTItTRng0T250FrVldPstnFx" ;
VAL_ 2583499006 MeasurementTime 0 "midnight,__time_is_in_UTC" ;
VAL_ 2583499006 TideTendency 11 "Unavailable,_Unknown" 10 "Error" 1 "Rising" 0 "Falling" ;
VAL_ 2583499006 Mode 15 "Data_not_available" 14 "Error" 4 "Manual_mode" 3 "Simulator_mode" 2 "Estimated_mode" 1 "Differential,_enhanced_mode" 0 "Autonomous_mode" ;
VAL_ 2381320446 Time 0 "midnight,__time_is_in_UTC" ;
VAL_ 2381320446 Source 15 "Null" 14 "reserved" 5 "Local_Crystal_clock,_" 0 "-" 4 "Local" 0 "clock" 3 "Local" 0 "clock" 2 "WWVEqvalentRadioStationTimeSync" 1 "GLONASS" 0 "GPS" ;
VAL_ 2381320446 SID 255 "nVldPsFxTTItTRng0T250FrVldPstnFx" ;
VAL_ 2381451006 Switch28 3 "No_action" 2 "Reserved" 1 "TurnOnEnableSetMake1" 0 "TurnOffDisableResetMake0" ;
VAL_ 2381451006 Switch27 3 "No_action" 2 "Reserved" 1 "TurnOnEnableSetMake1" 0 "TurnOffDisableResetMake0" ;
VAL_ 2381451006 Switch26 3 "No_action" 2 "Reserved" 1 "TurnOnEnableSetMake1" 0 "TurnOffDisableResetMake0" ;
VAL_ 2381451006 Switch25 3 "No_action" 2 "Reserved" 1 "TurnOnEnableSetMake1" 0 "TurnOffDisableResetMake0" ;
VAL_ 2381451006 Switch24 3 "No_action" 2 "Reserved" 1 "TurnOnEnableSetMake1" 0 "TurnOffDisableResetMake0" ;
VAL_ 2381451006 Switch23 3 "No_action" 2 "Reserved" 1 "TurnOnEnableSetMake1" 0 "TurnOffDisableResetMake0" ;
VAL_ 2381451006 Switch22 3 "No_action" 2 "Reserved" 1 "TurnOnEnableSetMake1" 0 "TurnOffDisableResetMake0" ;
VAL_ 2381451006 Switch21 3 "No_action" 2 "Reserved" 1 "TurnOnEnableSetMake1" 0 "TurnOffDisableResetMake0" ;
VAL_ 2381451006 Switch20 3 "No_action" 2 "Reserved" 1 "TurnOnEnableSetMake1" 0 "TurnOffDisableResetMake0" ;
VAL_ 2381451006 Switch19 3 "No_action" 2 "Reserved" 1 "TurnOnEnableSetMake1" 0 "TurnOffDisableResetMake0" ;
VAL_ 2381451006 Switch18 3 "No_action" 2 "Reserved" 1 "TurnOnEnableSetMake1" 0 "TurnOffDisableResetMake0" ;
VAL_ 2381451006 Switch17 3 "No_action" 2 "Reserved" 1 "TurnOnEnableSetMake1" 0 "TurnOffDisableResetMake0" ;
VAL_ 2381451006 Switch16 3 "No_action" 2 "Reserved" 1 "TurnOnEnableSetMake1" 0 "TurnOffDisableResetMake0" ;
VAL_ 2381451006 Switch15 3 "No_action" 2 "Reserved" 1 "TurnOnEnableSetMake1" 0 "TurnOffDisableResetMake0" ;
VAL_ 2381451006 Switch14 3 "No_action" 2 "Reserved" 1 "TurnOnEnableSetMake1" 0 "TurnOffDisableResetMake0" ;
VAL_ 2381451006 Switch13 3 "No_action" 2 "Reserved" 1 "TurnOnEnableSetMake1" 0 "TurnOffDisableResetMake0" ;
VAL_ 2381451006 Switch12 3 "No_action" 2 "Reserved" 1 "TurnOnEnableSetMake1" 0 "TurnOffDisableResetMake0" ;
VAL_ 2381451006 Switch11 3 "No_action" 2 "Reserved" 1 "TurnOnEnableSetMake1" 0 "TurnOffDisableResetMake0" ;
VAL_ 2381451006 Switch10 3 "No_action" 2 "Reserved" 1 "TurnOnEnableSetMake1" 0 "TurnOffDisableResetMake0" ;
VAL_ 2381451006 Switch9 3 "No_action" 2 "Reserved" 1 "TurnOnEnableSetMake1" 0 "TurnOffDisableResetMake0" ;
VAL_ 2381451006 Switch8 3 "No_action" 2 "Reserved" 1 "TurnOnEnableSetMake1" 0 "TurnOffDisableResetMake0" ;
VAL_ 2381451006 Switch7 3 "No_action" 2 "Reserved" 1 "TurnOnEnableSetMake1" 0 "TurnOffDisableResetMake0" ;
VAL_ 2381451006 Switch6 3 "No_action" 2 "Reserved" 1 "TurnOnEnableSetMake1" 0 "TurnOffDisableResetMake0" ;
VAL_ 2381451006 Switch5 3 "No_action" 2 "Reserved" 1 "TurnOnEnableSetMake1" 0 "TurnOffDisableResetMake0" ;
VAL_ 2381451006 Switch4 3 "No_action" 2 "Reserved" 1 "TurnOnEnableSetMake1" 0 "TurnOffDisableResetMake0" ;
VAL_ 2381451006 Switch3 3 "No_action" 2 "Reserved" 1 "TurnOnEnableSetMake1" 0 "TurnOffDisableResetMake0" ;
VAL_ 2381451006 Switch2 3 "No_action" 2 "Reserved" 1 "TurnOnEnableSetMake1" 0 "TurnOffDisableResetMake0" ;
VAL_ 2381451006 Switch1 3 "No_action" 2 "Reserved" 1 "TurnOnEnableSetMake1" 0 "TurnOffDisableResetMake0" ;
VAL_ 2314535934 SpeedWaterReferencedType 597 "DoNotChange_NotAvailable" 596 "Error" 595 "Not_Supported" 4 "EM_LogElectroMagnetic" 3 "Correlation_LogUltraSound" 2 "Doppler_Log" 1 "Pitot_Tube" 0 "Paddle_Wheel" ;
VAL_ 2314535934 SequenceID_ 255 "nVldPsFxTTItTRng0T250FrVldPstnFx" ;
VAL_ 2381908990 SetReference 3 "Null" 2 "Error" 1 "Magnetic" 0 "True" ;
VAL_ 2381908990 SID 255 "nVldPsFxTTItTRng0T250FrVldPstnFx" ;
VAL_ 2314277886 SequenceID_ 255 "nVldPsFxTTItTRng0T250FrVldPstnFx" ;
VAL_ 2314732542 SequenceID_ 255 "nVldPsFxTTItTRng0T250FrVldPstnFx" ;
VAL_ 2583234046 SpplmntaryRoute_WPDataAvailable 3 "[Unavailable,_Unknown]" 2 "Error" 1 "[Yes,_On,_Enabled,_Set,_'1']" 0 "[No,_Off,_Disabled,_Reset,_'0']" ;
VAL_ 2381907198 ETATime 0 "midnight,__time_is_in_UTC" ;
VAL_ 2381907198 CalculationType 3 "Null" 2 "Error" 1 "Rhumb_Line_calculations" 0 "Great_Circle_calculations" ;
VAL_ 2381907198 ArrivalCircleEntered 3 "[Unavailable,_Unknown]" 2 "Error" 1 "[Yes,_On,_Enabled,_Set,_'1']" 0 "[No,_Off,_Disabled,_Reset,_'0']" ;
VAL_ 2381907198 PerpendicularCrossed 3 "[Unavailable,_Unknown]" 2 "Error" 1 "[Yes,_On,_Enabled,_Set,_'1']" 0 "[No,_Off,_Disabled,_Reset,_'0']" ;
VAL_ 2381907198 Course_BearingRef 3 "Null" 2 "Error" 1 "Magnetic" 0 "True" ;
VAL_ 2381907198 SID 255 "nVldPsFxTTItTRng0T250FrVldPstnFx" ;
VAL_ 2381184766 VrblNmbrOfFldsFldNmber6Repeated3 5 "RqCmdGroupFunctionNotSupported" 4 "Access_denied" 3 "RqCmdParameterOutofrange" 2 "Temporarily_unable_to_comply" 1 "InvalidRqCmdParameterField" 0 "No_Error/Acknowledge" ;
VAL_ 2381184766 FirstParameterErrorCode 5 "RqCmdGroupFunctionNotSupported" 4 "Access_denied" 3 "RqCmdParameterOutofrange" 2 "Temporarily_unable_to_comply" 1 "InvalidRqCmdParameterField" 0 "No_Error/Acknowledge" ;
VAL_ 2381184766 TransInterval_PriorityErrorCode 4 "Request_is_not_supported" 3 "Access_denied" 2 "TrnsmtIntrvlIsLssThnMsrmnt_Clclt" 1 "TrnsmtIntrvl_PrrityNotSupported" 0 "No_Error/Acknowledge" ;
VAL_ 2381184766 PGNErrorCode 4 "Request_is_not_supported" 3 "Access_denied" 2 "PGN_temporarily_not_available" 1 "PGN_not_supported" 0 "No_Error/Acknowledge" ;
VAL_ 2381184766 PrioritySetting 15 "reserved" 9 "returnPriorityToDefault0xATo" 8 "do_not_change_priority" 7 "commanded_priority_value" ;
VAL_ 2381184766 TransIntervalOffset 65535 "Do_not_change_offset" 0 "transmit_immediately" ;
VAL_ 2381184766 TransInterval 65535 "Do_not_change_interval" 0 "Turn-off_transmission" ;
VAL_ 2381184766 GroupFunctionRq_Cmd_Acknowledge 2 "Acknowledge_Message" 1 "Command_Message" 0 "Request_Message" ;
VAL_ 2583500030 WindReference 7 "Null" 6 "Error" 5 "Reserved" 3 "True_boat_referenced" 2 "Apparent" 1 "Magnetic" 0 "True_referenced_to_North" ;
VAL_ 2583500030 MeasurementTime 0 "midnight,__time_is_in_UTC" ;
VAL_ 2583500030 Mode 15 "Data_not_available" 14 "Error" 4 "Manual_mode" 3 "Simulator_mode" 2 "Estimated_mode" 1 "Differential,_enhanced_mode" 0 "Autonomous_mode" ;
VAL_ 2583499774 WindReference 7 "Null" 6 "Error" 5 "Reserved" 3 "True_boat_referenced" 2 "Apparent" 1 "Magnetic" 0 "True_referenced_to_North" ;
VAL_ 2583499774 MeasurementTime 0 "midnight,__time_is_in_UTC" ;
VAL_ 2583499774 Mode 15 "Data_not_available" 14 "Error" 4 "Manual_mode" 3 "Simulator_mode" 2 "Estimated_mode" 1 "Differential,_enhanced_mode" 0 "Autonomous_mode" ;
VAL_ 2649823998 VariationSource 63 "Data_Not_Available" 62 "Reserve" 9 "Reserve," 0 "8" 0 "2020" 7 "WMM" 2015 "6" 0 "2010" 5 "WMM" 2005 "4" 0 "2000" 3 "Automatic" 0 "2" 0 "Table" 1 "Automatic" 0 "Chart" 0 "Manual" ;
VAL_ 2649823998 SequenceID_ 255 "nVldPsFxTTItTRng0T250FrVldPstnFx" ;
VAL_ 2382103806 Mode 15 "Data_not_available" 14 "Error" 4 "Manual_mode" 3 "Simulator_mode" 2 "Estimated_mode" 1 "Differential,_enhanced_mode" 0 "Autonomous_mode" ;
VAL_ 2382103806 GroupRepetitionInterval 9960 "99,600,000_ns" ;
VAL_ 2382104318 GroupRepetitionInterval 9960 "99,600,000_ns" ;
VAL_ 2382104062 Mode 15 "Data_not_available" 14 "Error" 4 "Manual_mode" 3 "Simulator_mode" 2 "Estimated_mode" 1 "Differential,_enhanced_mode" 0 "Autonomous_mode" ;
VAL_ 2382104062 GroupRepetitionInterval 9960 "99,600,000_ns" ;
VAL_ 2314274302 CmdedRudderDirection 2 "Move_to_port" 1 "Move_to_starboard" 0 "No_Order" ;
VAL_ 2314274302 HeadingReference 3 "Null" 2 "Error" 1 "Magnetic" 0 "True" ;
VAL_ 2314274302 TurnMode 2 "rdsCtrlldDfntnsRddrAnOprtrStRddr" 1 "turn_rate_controlled" 0 "Rudder_Limit_controlled" ;
VAL_ 2314274302 SteerMode 2 "Follow-up_Device" 1 "Non-Follow-up_Device" 0 "Main_Steering" 5 "TrckCtrlDfntnsMnStr_OtsdSystmMnS" 4 "Heading_Control" 3 "Heading_Control_Standalone" ;
VAL_ 2314274302 Override 0 "NYsMnsATmprryIntrrptnOfSlctdStrM" 1 "Yes" ;
VAL_ 2314274302 OffTrackLimitExceeded 3 "[Unavailable,_Unknown]" 2 "Error" 1 "[Yes,_On,_Enabled,_Set,_'1']" 0 "[No,_Off,_Disabled,_Reset,_'0']" ;
VAL_ 2314274302 OffHeadingLimitExceeded 3 "[Unavailable,_Unknown]" 2 "Error" 1 "[Yes,_On,_Enabled,_Set,_'1']" 0 "[No,_Off,_Disabled,_Reset,_'0']" ;
VAL_ 2314274302 RudderLimitExceeded 3 "[Unavailable,_Unknown]" 2 "Error" 1 "[Yes,_On,_Enabled,_Set,_'1']" 0 "[No,_Off,_Disabled,_Reset,_'0']" ;
VAL_ 2583299582 PRN 96 "GLONASSFrGLONASSStlltsArIdntfdBy" 64 "SBASStlltBsdAgmentationSystem65" 1 "GPS,_" 33 "0" 0 "not" ;
VAL_ 2583299326 PRNStatusN 6 "Reserved14Error15NoSelection" 5 "usedWithDiffCorrections" 4 "TrackedWithDiffCorrections" 3 "DiffCorrectionsAvailable" 2 "UsdInSltnWithoutDiffCorrections" 1 "TrackedButNotUsedInSolution" 0 "Not_Tracked" ;
VAL_ 2583299326 PRNN 96 "GLONASSFrGLONASSStlltsArIdntfdBy" 64 "SBASStlltBsdAgmentationSystem65" 1 "GPS,_" 33 "0" 0 "not" ;
VAL_ 2583299326 PRNStatus1 6 "Reserved14Error15NoSelection" 5 "usedWithDiffCorrections" 4 "TrackedWithDiffCorrections" 3 "DiffCorrectionsAvailable" 2 "UsdInSltnWithoutDiffCorrections" 1 "TrackedButNotUsedInSolution" 0 "Not_Tracked" ;
VAL_ 2583299326 PRN1 96 "GLONASSFrGLONASSStlltsArIdntfdBy" 64 "SBASStlltBsdAgmentationSystem65" 1 "GPS,_" 33 "0" 0 "not" ;
VAL_ 2583299326 SID 255 "nVldPsFxTTItTRng0T250FrVldPstnFx" ;
VAL_ 2583299326 RangeResidualMode 3 "Null" 2 "Error" 1 "RangeResidualCalculateddAfterPos" 0 "RangeResidualWereUsedtoCalcData" ;
VAL_ 2583238398 DestinationMarkType 15 "Null" 14 "Error" 5 "Reserved" 4 "Waypoint" 3 "Wheelover" 2 "Reference_general" 1 "Turning_Point" 0 "Collision" ;
VAL_ 2583238398 OriginMarkType 15 "Null" 14 "Error" 5 "Reserved" 4 "Waypoint" 3 "Wheelover" 2 "Reference_general" 1 "Turning_Point" 0 "Collision" ;
VAL_ 2583238398 CalculationType 3 "Null" 2 "Error" 1 "Rhumb_Line_calculations" 0 "Great_Circle_calculations" ;
VAL_ 2583238398 BearingRef 3 "Null" 2 "Error" 1 "Magnetic" 0 "True" ;
VAL_ 2583238398 SID 255 "nVldPsFxTTItTRng0T250FrVldPstnFx" ;
VAL_ 2381450750 Indic28 3 "[Unavailable,_Unknown]" 2 "Error" 1 "[Yes,_On,_Enabled,_Set,_'1']" 0 "[No,_Off,_Disabled,_Reset,_'0']" ;
VAL_ 2381450750 Indic27 3 "[Unavailable,_Unknown]" 2 "Error" 1 "[Yes,_On,_Enabled,_Set,_'1']" 0 "[No,_Off,_Disabled,_Reset,_'0']" ;
VAL_ 2381450750 Indic26 3 "[Unavailable,_Unknown]" 2 "Error" 1 "[Yes,_On,_Enabled,_Set,_'1']" 0 "[No,_Off,_Disabled,_Reset,_'0']" ;
VAL_ 2381450750 Indic25 3 "[Unavailable,_Unknown]" 2 "Error" 1 "[Yes,_On,_Enabled,_Set,_'1']" 0 "[No,_Off,_Disabled,_Reset,_'0']" ;
VAL_ 2381450750 Indic24 3 "[Unavailable,_Unknown]" 2 "Error" 1 "[Yes,_On,_Enabled,_Set,_'1']" 0 "[No,_Off,_Disabled,_Reset,_'0']" ;
VAL_ 2381450750 Indic23 3 "[Unavailable,_Unknown]" 2 "Error" 1 "[Yes,_On,_Enabled,_Set,_'1']" 0 "[No,_Off,_Disabled,_Reset,_'0']" ;
VAL_ 2381450750 Indic22 3 "[Unavailable,_Unknown]" 2 "Error" 1 "[Yes,_On,_Enabled,_Set,_'1']" 0 "[No,_Off,_Disabled,_Reset,_'0']" ;
VAL_ 2381450750 Indic21 3 "[Unavailable,_Unknown]" 2 "Error" 1 "[Yes,_On,_Enabled,_Set,_'1']" 0 "[No,_Off,_Disabled,_Reset,_'0']" ;
VAL_ 2381450750 Indic20 3 "[Unavailable,_Unknown]" 2 "Error" 1 "[Yes,_On,_Enabled,_Set,_'1']" 0 "[No,_Off,_Disabled,_Reset,_'0']" ;
VAL_ 2381450750 Indic19 3 "[Unavailable,_Unknown]" 2 "Error" 1 "[Yes,_On,_Enabled,_Set,_'1']" 0 "[No,_Off,_Disabled,_Reset,_'0']" ;
VAL_ 2381450750 Indic18 3 "[Unavailable,_Unknown]" 2 "Error" 1 "[Yes,_On,_Enabled,_Set,_'1']" 0 "[No,_Off,_Disabled,_Reset,_'0']" ;
VAL_ 2381450750 Indic17 3 "[Unavailable,_Unknown]" 2 "Error" 1 "[Yes,_On,_Enabled,_Set,_'1']" 0 "[No,_Off,_Disabled,_Reset,_'0']" ;
VAL_ 2381450750 Indic16 3 "[Unavailable,_Unknown]" 2 "Error" 1 "[Yes,_On,_Enabled,_Set,_'1']" 0 "[No,_Off,_Disabled,_Reset,_'0']" ;
VAL_ 2381450750 Indic15 3 "[Unavailable,_Unknown]" 2 "Error" 1 "[Yes,_On,_Enabled,_Set,_'1']" 0 "[No,_Off,_Disabled,_Reset,_'0']" ;
VAL_ 2381450750 Indic14 3 "[Unavailable,_Unknown]" 2 "Error" 1 "[Yes,_On,_Enabled,_Set,_'1']" 0 "[No,_Off,_Disabled,_Reset,_'0']" ;
VAL_ 2381450750 Indic13 3 "[Unavailable,_Unknown]" 2 "Error" 1 "[Yes,_On,_Enabled,_Set,_'1']" 0 "[No,_Off,_Disabled,_Reset,_'0']" ;
VAL_ 2381450750 Indic12 3 "[Unavailable,_Unknown]" 2 "Error" 1 "[Yes,_On,_Enabled,_Set,_'1']" 0 "[No,_Off,_Disabled,_Reset,_'0']" ;
VAL_ 2381450750 Indic11 3 "[Unavailable,_Unknown]" 2 "Error" 1 "[Yes,_On,_Enabled,_Set,_'1']" 0 "[No,_Off,_Disabled,_Reset,_'0']" ;
VAL_ 2381450750 Indic10 3 "[Unavailable,_Unknown]" 2 "Error" 1 "[Yes,_On,_Enabled,_Set,_'1']" 0 "[No,_Off,_Disabled,_Reset,_'0']" ;
VAL_ 2381450750 Indic9 3 "[Unavailable,_Unknown]" 2 "Error" 1 "[Yes,_On,_Enabled,_Set,_'1']" 0 "[No,_Off,_Disabled,_Reset,_'0']" ;
VAL_ 2381450750 Indic8 3 "[Unavailable,_Unknown]" 2 "Error" 1 "[Yes,_On,_Enabled,_Set,_'1']" 0 "[No,_Off,_Disabled,_Reset,_'0']" ;
VAL_ 2381450750 Indic7 3 "[Unavailable,_Unknown]" 2 "Error" 1 "[Yes,_On,_Enabled,_Set,_'1']" 0 "[No,_Off,_Disabled,_Reset,_'0']" ;
VAL_ 2381450750 Indic6 3 "[Unavailable,_Unknown]" 2 "Error" 1 "[Yes,_On,_Enabled,_Set,_'1']" 0 "[No,_Off,_Disabled,_Reset,_'0']" ;
VAL_ 2381450750 Indic5 3 "[Unavailable,_Unknown]" 2 "Error" 1 "[Yes,_On,_Enabled,_Set,_'1']" 0 "[No,_Off,_Disabled,_Reset,_'0']" ;
VAL_ 2381450750 Indic4 3 "[Unavailable,_Unknown]" 2 "Error" 1 "[Yes,_On,_Enabled,_Set,_'1']" 0 "[No,_Off,_Disabled,_Reset,_'0']" ;
VAL_ 2381450750 Indic3 3 "[Unavailable,_Unknown]" 2 "Error" 1 "[Yes,_On,_Enabled,_Set,_'1']" 0 "[No,_Off,_Disabled,_Reset,_'0']" ;
VAL_ 2381450750 Indic2 3 "[Unavailable,_Unknown]" 2 "Error" 1 "[Yes,_On,_Enabled,_Set,_'1']" 0 "[No,_Off,_Disabled,_Reset,_'0']" ;
VAL_ 2381450750 Indic1 3 "[Unavailable,_Unknown]" 2 "Error" 1 "[Yes,_On,_Enabled,_Set,_'1']" 0 "[No,_Off,_Disabled,_Reset,_'0']" ;
VAL_ 2582779134 SID 255 "nVldPsFxTTItTRng0T250FrVldPstnFx" ;
VAL_ 2381388286 SID 255 "nVldPsFxTTItTRng0T250FrVldPstnFx" ;
VAL_ 2314732798 Direction 3 "Null" 2 "Error" 1 "Magnetic" 0 "True" ;
VAL_ 2314732798 GNSSQuality 15 "NllPrcsGNSSMnsNDlbrtDgrdtnAndHgh" 14 "Error" 9 "Reserved" 8 "Simulate_mode" 7 "Manual_Input" 6 "Estimated_DR_mode" 5 "RTK_Float" 4 "RTK_Fixed_Integer" 3 "Precise_GNSS*" 2 "DGNSS_fix" 1 "GNSS_fix" 0 "no_GPS" ;
VAL_ 2314732798 SequenceID_ 255 "nVldPsFxTTItTRng0T250FrVldPstnFx" ;
VAL_ 2650474750 AISTransceiverInformation 4 "Own_information_not_broadcast" 3 "Channel_B_VDL_transmission" 5 "Reserved" 2 "Channel_A_VDL_transmission" 1 "Channel_B_VDL_reception" 0 "Channel_A_VDL_reception" ;
VAL_ 2650474750 RepeatIndicator 3 "FnlRTrnsSITURM13711FrMrInfrmton" 2 "Second_retransmission" 1 "First_retransmission" 0 "Default" ;
VAL_ 2650472958 TypeOfElectronicPosingDevice 8 "RsrvFrFtrUsSITURM13711FrMrInfrmt" ;
VAL_ 2650472958 AISTransceiverInformation 4 "Own_information_not_broadcast" 3 "Channel_B_VDL_transmission" 5 "Reserved" 2 "Channel_A_VDL_transmission" 1 "Channel_B_VDL_reception" 0 "Channel_A_VDL_reception" ;
VAL_ 2650472958 PosTime 0 "midnight,__time_is_in_UTC" ;
VAL_ 2650472958 RAIMflag 1 "RAIMInUsSITURM13711FrMrInfrmton" 0 "RAIM_not_in_use_default" ;
VAL_ 2650472958 RepeatIndicator 3 "FnlRTrnsSITURM13711FrMrInfrmton" 2 "Second_retransmission" 1 "First_retransmission" 0 "Default" ;
VAL_ 2650475262 AISTransceiverInformation 4 "Own_information_not_broadcast" 3 "Channel_B_VDL_transmission" 5 "Reserved" 2 "Channel_A_VDL_transmission" 1 "Channel_B_VDL_reception" 0 "Channel_A_VDL_reception" ;
VAL_ 2650475262 RepeatIndicator 3 "FnlRTrnsSITURM13711FrMrInfrmton" 2 "Second_retransmission" 1 "First_retransmission" 0 "Default" ;
VAL_ 2650474238 AISTransceiverInformation 4 "Own_information_not_broadcast" 3 "Channel_B_VDL_transmission" 5 "Reserved" 2 "Channel_A_VDL_transmission" 1 "Channel_B_VDL_reception" 0 "Channel_A_VDL_reception" ;
VAL_ 2650474238 TimeStamp 63 "PsngSystmIsInprtvSITURM13711FrMr" 62 "ElctrncPsFxngSystmOprtsInEstMde" 61 "PosingSystemIsInManualInputMode" 60 "timeStampNotAvailable" 0 "UTCSecondWhenReportWasGenerated" ;
VAL_ 2650474238 RAIMFlag 1 "RAIMInUsSITURM13711FrMrInfrmton" 0 "RAIM_not_in_use_default" ;
VAL_ 2650474238 RepeatIndicator 3 "FnlRTrnsSITURM13711FrMrInfrmton" 2 "Second_retransmission" 1 "First_retransmission" 0 "Default" ;
VAL_ 2650475518 AISTransceiverInformation 4 "Own_information_not_broadcast" 3 "Channel_B_VDL_transmission" 5 "Reserved" 2 "Channel_A_VDL_transmission" 1 "Channel_B_VDL_reception" 0 "Channel_A_VDL_reception" ;
VAL_ 2650475518 RepeatIndicator 3 "FnlRTrnsSITURM13711FrMrInfrmton" 2 "Second_retransmission" 1 "First_retransmission" 0 "Default" ;
VAL_ 2650476030 AISTransceiverInformation 4 "Own_information_not_broadcast" 3 "Channel_B_VDL_transmission" 5 "Reserved" 2 "Channel_A_VDL_transmission" 1 "Channel_B_VDL_reception" 0 "Channel_A_VDL_reception" ;
VAL_ 2650476030 RepeatIndicator 3 "FnlRTrnsSITURM13711FrMrInfrmton" 2 "Second_retransmission" 1 "First_retransmission" 0 "Default" ;
VAL_ 2583363838 AISTransceiverInformation 4 "Own_information_not_broadcast" 3 "Channel_B_VDL_transmission" 5 "Reserved" 2 "Channel_A_VDL_transmission" 1 "Channel_B_VDL_reception" 0 "Channel_A_VDL_reception" ;
VAL_ 2583363838 RepeatIndicator 3 "FnlRTrnsSITURM13711FrMrInfrmton" 2 "Second_retransmission" 1 "First_retransmission" 0 "Default" ;
VAL_ 2650473214 RepeatIndicator 3 "FnlRTrnsSITURM13711FrMrInfrmton" 2 "Second_retransmission" 1 "First_retransmission" 0 "Default" ;
VAL_ 2448953342 AISTransceiverInformation 4 "Own_information_not_broadcast" 3 "Channel_B_VDL_transmission" 5 "Reserved" 2 "Channel_A_VDL_transmission" 1 "Channel_B_VDL_reception" 0 "Channel_A_VDL_reception" ;
VAL_ 2448953342 TimeStamp 63 "PsngSystmIsInprtvSITURM13711FrMr" 62 "ElctrncPsFxngSystmOprtsInEstMde" 61 "PosingSystemIsInManualInputMode" 60 "timeStampNotAvailable" 0 "UTCSecondWhenReportWasGenerated" ;
VAL_ 2448953342 RAIMflag 1 "RAIMInUsSITURM13711FrMrInfrmton" 0 "RAIM_not_in_use_default" ;
VAL_ 2448953342 RepeatIndicator 3 "FnlRTrnsSITURM13711FrMrInfrmton" 2 "Second_retransmission" 1 "First_retransmission" 0 "Default" ;
VAL_ 2448953598 TypeOfElectronicPosingDevice 8 "RsrvFrFtrUsSITURM13711FrMrInfrmt" ;
VAL_ 2448953598 Ship_CargoType 255 "ReservedForFuture" 199 "ReservedForRegional200" 1 "100" ;
VAL_ 2448953598 TimeStamp 63 "PsngSystmIsInprtvSITURM13711FrMr" 62 "ElctrncPsFxngSystmOprtsInEstMde" 61 "PosingSystemIsInManualInputMode" 60 "timeStampNotAvailable" 0 "UTCSecondWhenReportWasGenerated" ;
VAL_ 2448953598 RAIMflag 1 "RAIMInUsSITURM13711FrMrInfrmton" 0 "RAIM_not_in_use_default" ;
VAL_ 2448953598 RepeatIndicator 3 "FnlRTrnsSITURM13711FrMrInfrmton" 2 "Second_retransmission" 1 "First_retransmission" 0 "Default" ;
VAL_ 2566838526 IndustryGroup 6 "Reserved_for_SAE" 7 "Reserved_for_SAE" 5 "IndustrialProcessCtrlStationary" 4 "Marine" 3 "Construction" 2 "Agricultural_and_Forestry" 1 "On-Highway" 0 "Global" ;
VAL_ 2566838526 Function 127 "Reserved" 126 "Reserved" 125 "Reserved" 124 "Reserved" 123 "Reserved" 122 "Reserved" 121 "Reserved" 120 "Reserved" 119 "Reserved" 118 "Reserved" 117 "Reserved" 116 "Reserved" 115 "Reserved" 114 "Reserved" 113 "Reserved" 112 "Reserved" 111 "Reserved" 110 "Reserved" 109 "Reserved" 108 "Reserved" 107 "Reserved" 106 "Reserved" 105 "Reserved" 104 "Reserved" 103 "Reserved" 102 "Reserved" 101 "Reserved" 42 "Water_Pump_Control" 41 "Lighting_-_Operator_Controls" 40 "Seat_Control" 39 "Ignition_Control_Module" 38 "Tire_Pressure_Control" 37 "Cab_Controller" 36 "Pneumatic_-_System_Controller" 35 "Suspension_-_System_Controller" 34 "Hydraulic_Pump_Controller" 33 "System_Monitor" 32 "Headway_Controller" 31 "Propulsion_Battery_Charger" 30 "Management_Computer" 29 "Virtual_Terminal_in_cab" 28 "Off_Vehicle_Gateway" 27 "Power_TakeOff_Secondary_or_Front" 26 "Body_Controller" 25 "Network_Interconnect_ECU" 24 "Vehicle_Security" 23 "Vehicle_Navigation" 22 "Aerodynamic_Control" 21 "Cab_Climate_Control" 20 "Trip_Recorder" 19 "Instrument_Cluster" 18 "Suspension_-_Drive_Axle" 17 "Suspension_-_Steer_Axle" 16 "Steering_Controller" 15 "Fuel_System" 14 "Cruise_Control" 13 "Retarder_-_Driveline" 12 "Retarder_-_Engine" 11 "Brakes_-_Drive_Axle" 10 "Brakes_-_Steer_Axle" 9 "Brakes_-_System_Controller" 8 "Axle_-_Drive" 7 "Axle_-_Steering" 6 "Power_TakeOff_-_Main_or_Rear" 5 "Shift_Control/Console" 4 "Battery_Pack_Monitor" 3 "Transmission" 2 "Electric_Propulsion_Control" 1 "Auxiliary_Power_Unit_APU" 0 "Engine" 100 "Reserved" 99 "Reserved" 98 "Reserved" 97 "Reserved" 96 "Reserved" 95 "Reserved" 94 "Reserved" 93 "Reserved" 92 "Reserved" 91 "Reserved" 90 "Reserved" 89 "Reserved" 88 "Reserved" 87 "Reserved" 86 "Reserved" 85 "Reserved" 84 "Reserved" 83 "Reserved" 82 "Reserved" 81 "Reserved" 80 "Reserved" 79 "Reserved" 78 "Reserved" 77 "Reserved" 76 "Reserved" 75 "Supplemental_Fan" 74 "Lubrication_System" 73 "Rollover_Detection_Control" 72 "Coolant_Valve_Controller" 71 "Transfer_Case_Control" 70 "Auxiliary_Regeneration_Device" 69 "Engine_Emission_Aftertreatement_System" 68 "Aftertreatment_system_gas_measurement" 67 "Electrical_System_Controller" 66 "I/O_Controller" 65 "Gas_Flow_Measurement" 64 "Endurance_Braking" 63 "Engine_Valve_Controller" 62 "On-Board_Diagnostic_Unit" 61 "File_Server/Printer" 60 "Cab_Display" 59 "Starter" 58 "Fan_Drive_Control" 57 "Steering_Column_Unit" 56 "Communications_Unit,_Radio" 55 "Communications_Unit,_Satellite" 54 "Communications_Unit,_Cellular" 53 "Alternator/Charging_System" 52 "Chassis_Controller" 51 "Forward-Looking_Collision_Warning_System" 50 "Auxiliary_Heater" 49 "Clutch/Converter_Control" 48 "Ramp_Control" 47 "Information_System_Controller" 46 "Oil_Sensor_Unit" 45 "Vehicle_Dynamic_Stability_Control" 44 "Exhaust_Emission_Control" 43 "Transmission_Display" ;
VAL_ 2566838526 VehicleSystem 0 "Non-specific_System" 127 "Not_Available" ;
VAL_ 2566838526 VehicleSystem5 127 "Not_Available" 0 "Ind._Process_Control_Stationary" ;
VAL_ 2566838526 VehicleSystem4 125 "Entertainment" 120 "Display" 85 "External_Environment" 75 "Sensor_Communication_Interface" 35 "Electrical_Generation" 100 "Deck,_Cargo_and_Fishing_Equipment" 90 "Internal_Environment" 80 "Instrumentation/General_Systems_deprecate" 70 "Communications" 60 "Navigation" 50 "Propulsion" 40 "Steering_and_Control_Surfaces" 30 "Electrical_Distribution" 25 "Inter/Intranetwork_Device" 20 "Safety_Systems" 10 "System_Tools" 127 "Not_Available" 0 "Non-specific_System" ;
VAL_ 2566838526 VehicleSystem3 8 "Grader" 7 "Four_Wheel_Drive_Loader" 6 "Forklift" 5 "Excavator" 4 "Crawler" 3 "Backhoe" 2 "Articulated_Dump_Truck" 1 "Skid_Steer_Loader" 127 "Not_Available" 0 "Non-specific_System" ;
VAL_ 2566838526 VehicleSystem2 16 "Skidder" 15 "Earth_Work" 14 "Special_Crops" 13 "Powered_Auxiliary_Device" 12 "Farm_Yard_Operations" 11 "Transport/Trailer" 10 "Irrigation" 9 "Forage" 8 "Root_Harvesters" 7 "Harvesters" 6 "Sprayers" 5 "Fertilizers" 4 "Planters/Seeders" 3 "Secondary_Tillage" 2 "Tillage" 1 "Tractor" 127 "Not_Available" 0 "Non-specific_System" ;
VAL_ 2566838526 VehicleSystem1 2 "Trailer" 1 "Tractor" 127 "Not_Available" 0 "Non-specific_System" ;
